VERSION ""

NS_ :

BS_:

BU_: FUSION IVI HMI Telltale

BO_ 278 FD_VCU1: 8 FUSION
 SG_ XWDMode : 57|2@0+ (1,0) [0|2] "" IVI
 SG_ PwrSta : 63|3@0+ (1,0) [0|5] "" IVI,HMI,Telltale
 SG_ DCDCVoltSetpoint : 55|8@0+ (0.0235,12) [12|17.9925] "V" Vector__XXX
 SG_ DCDCEnaReq : 40|1@0+ (1,0) [0|1] "" Vector__XXX
 SG_ Fr_MCUEnaReq : 41|1@0+ (1,0) [0|1] "" Vector__XXX
 SG_ Rr_MCUEnaReq : 42|1@0+ (1,0) [0|1] "" Vector__XXX
 SG_ HVBatCnctReq : 43|1@0+ (1,0) [0|1] "" Vector__XXX
 SG_ ActiveDischReq : 44|1@0+ (1,0) [0|1] "" Vector__XXX
 SG_ PrkReq : 45|1@0+ (1,0) [0|1] "" Vector__XXX
 SG_ Fr_ActvDmpDisabReq : 46|1@0+ (1,0) [0|1] "" Vector__XXX
 SG_ Rr_ActvDmpDisabReq : 47|1@0+ (1,0) [0|1] "" Vector__XXX
 SG_ HVSysReadyToCharge : 33|2@0+ (1,0) [0|3] "" Vector__XXX
 SG_ ShiftGearPosn : 38|3@0+ (1,0) [0|7] "" IVI
 SG_ LVChrgFuncStaChk : 25|2@0+ (1,0) [0|2] "" IVI
 SG_ CC_Crl_Sta : 28|3@0+ (1,0) [0|7] "" IVI
 SG_ MSA_Crl_Sta : 31|3@0+ (1,0) [0|7] "" IVI
 SG_ DemoModeStaChk : 17|2@0+ (1,0) [0|2] "" IVI
 SG_ CoastDwModeStaChk : 19|2@0+ (1,0) [0|2] "" IVI
 SG_ DynoModeStaChk : 21|2@0+ (1,0) [0|2] "" IVI
 SG_ Dr_SeatSta : 23|2@0+ (1,0) [0|2] "" IVI
 SG_ FalseNPrevent_Sta : 8|1@0+ (1,0) [0|1] "" IVI
 SG_ DisengageP_Fail : 9|1@0+ (1,0) [0|1] "" IVI
 SG_ EngageP_Fail : 10|1@0+ (1,0) [0|1] "" IVI
 SG_ CreepSW_Sta : 11|1@0+ (1,0) [0|1] "" IVI
 SG_ RC_VCU1_CAN2 : 15|4@0+ (1,0) [0|15] "" Vector__XXX
 SG_ CS_VCU1_CAN2 : 7|8@0+ (1,0) [0|255] "" Vector__XXX
 SG_ VCU_OPDHold : 39|1@0+ (1,0) [0|1] "" IVI
 SG_ FDC_VCU_PwrSaveReq_Cmd : 35|1@0+ (1,0) [0|1] "" IVI

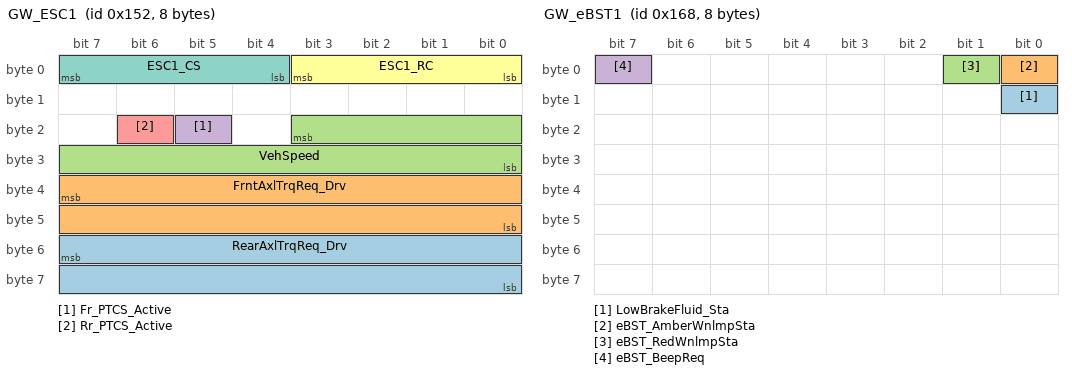
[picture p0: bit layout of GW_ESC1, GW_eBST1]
BO_ 338 GW_ESC1: 8 FUSION
 SG_ RearAxlTrqReq_Drv : 55|16@0+ (0.5,-5300) [0|5300] "Nm" Vector__XXX
 SG_ FrntAxlTrqReq_Drv : 39|16@0+ (0.5,-5300) [0|5300] "Nm" Vector__XXX
 SG_ VehSpeed : 19|12@0+ (0.125,0) [0|255.875] "km/h" IVI,HMI,Telltale
 SG_ Fr_PTCS_Active : 21|1@0+ (1,0) [0|1] "" Vector__XXX
 SG_ Rr_PTCS_Active : 22|1@0+ (1,0) [0|1] "" Vector__XXX
 SG_ ESC1_RC : 3|4@0+ (1,0) [0|15] "" Vector__XXX
 SG_ ESC1_CS : 7|4@0+ (1,0) [0|15] "" Vector__XXX

BO_ 360 GW_eBST1: 8 FUSION
 SG_ LowBrakeFluid_Sta : 8|1@0+ (1,0) [0|1] "" IVI
 SG_ eBST_AmberWnlmpSta : 0|1@0+ (1,0) [0|1] "" IVI,Telltale
 SG_ eBST_RedWnlmpSta : 1|1@0+ (1,0) [0|1] "" IVI
 SG_ eBST_BeepReq : 7|1@0+ (1,0) [0|1] "" IVI

BO_ 369 GW_BMS1: 16 FUSION
 SG_ HVBPwrAvailChrg30 : 115|12@0+ (0.2,0) [0|819] "KW" Vector__XXX
 SG_ HVBPwrAvailDchrg30 : 111|12@0+ (0.2,0) [0|819] "KW" Vector__XXX
 SG_ HVBPwrAvailChrg : 91|12@0+ (0.2,0) [0|819] "KW" Vector__XXX
 SG_ HVBPwrAvailDchrg : 87|12@0+ (0.2,0) [0|819] "KW" Vector__XXX
 SG_ HVBPwrAvailChrg60 : 67|12@0+ (0.2,0) [0|819] "KW" Vector__XXX
 SG_ HVBPwrAvailDchrg60 : 63|12@0+ (0.2,0) [0|819] "KW" Vector__XXX
 SG_ HVBattCurr : 46|15@0+ (0.1,-1000) [-1000|2276.5] "A" IVI
 SG_ HVBattVolt : 28|13@0+ (0.1,0) [0|819] "V" IVI
 SG_ BMSRolCnct_1 : 15|4@0+ (1,0) [0|15] "" Vector__XXX
 SG_ BMSChckSum_1 : 7|8@0+ (1,0) [0|255] "" Vector__XXX

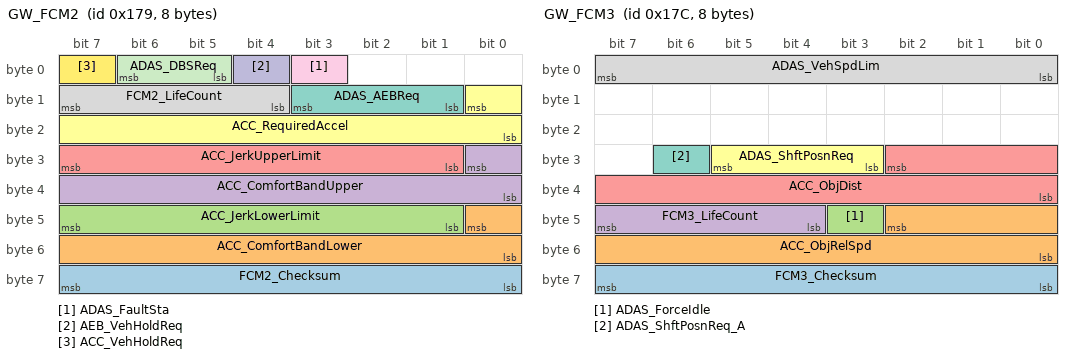
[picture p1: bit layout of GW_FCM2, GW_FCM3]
BO_ 377 GW_FCM2: 8 FUSION
 SG_ FCM2_Checksum : 63|8@0+ (1,0) [0|255] "" Vector__XXX
 SG_ ACC_ComfortBandLower : 40|9@0+ (0.05,-15) [-15|10.55] "m/s^2" Vector__XXX
 SG_ ACC_JerkLowerLimit : 47|7@0+ (0.1,-6) [-6|6.7] "m/s^3" Vector__XXX
 SG_ ACC_ComfortBandUpper : 24|9@0+ (0.05,-15) [-15|10.55] "m/s^2" Vector__XXX
 SG_ ACC_JerkUpperLimit : 31|7@0+ (0.1,-6) [-6|6.7] "m/s^3" Vector__XXX
 SG_ ACC_RequiredAccel : 8|9@0+ (0.05,-15) [-15|10.55] "m/s^2" Vector__XXX
 SG_ ADAS_AEBReq : 11|3@0+ (1,0) [0|7] "" IVI
 SG_ FCM2_LifeCount : 15|4@0+ (1,0) [0|15] "" Vector__XXX
 SG_ ADAS_FaultSta : 3|1@0+ (1,0) [0|1] "" Vector__XXX
 SG_ AEB_VehHoldReq : 4|1@0+ (1,0) [0|1] "" Vector__XXX
 SG_ ADAS_DBSReq : 6|2@0+ (1,0) [0|3] "" Vector__XXX
 SG_ ACC_VehHoldReq : 7|1@0+ (1,0) [0|1] "" Vector__XXX

BO_ 378 GW_BMS6: 12 FUSION
 SG_ BMS_Warn_1 : 88|1@0+ (1,0) [0|1] "" Vector__XXX
 SG_ BMS_Warn_2 : 89|1@0+ (1,0) [0|1] "" Vector__XXX
 SG_ BMS_Warn_3 : 90|1@0+ (1,0) [0|1] "" Vector__XXX
 SG_ BMS_Warn_4 : 91|1@0+ (1,0) [0|1] "" Vector__XXX
 SG_ BMS_Warn_5 : 92|1@0+ (1,0) [0|1] "" Vector__XXX
 SG_ BMS_Warn_6 : 93|1@0+ (1,0) [0|1] "" Vector__XXX
 SG_ BMS_Warn_7 : 94|1@0+ (1,0) [0|1] "" Vector__XXX
 SG_ BMS_Warn_8 : 95|1@0+ (1,0) [0|1] "" Vector__XXX
 SG_ HVBOvrTempWarn : 81|2@0+ (1,0) [0|2] "" IVI
 SG_ HVBUndrTempWarn : 83|2@0+ (1,0) [0|2] "" Vector__XXX
 SG_ HVBOvrVoltErr : 84|1@0+ (1,0) [0|1] "" Vector__XXX
 SG_ HVBUndrVoltErr : 85|1@0+ (1,0) [0|1] "" Vector__XXX
 SG_ HVBShrtChrgCurrErr : 86|1@0+ (1,0) [0|1] "" Vector__XXX
 SG_ HVBShrtDischrgCurrErr : 87|1@0+ (1,0) [0|1] "" Vector__XXX
 SG_ HVBOvrChrgCurrErr : 72|1@0+ (1,0) [0|1] "" Vector__XXX
 SG_ HVBOvrDchrgCurErr : 73|1@0+ (1,0) [0|1] "" Vector__XXX
 SG_ HVBOvrTempErr : 74|1@0+ (1,0) [0|1] "" IVI
 SG_ HVBUndrTempErr : 75|1@0+ (1,0) [0|1] "" Vector__XXX
 SG_ HVBOvrSOCErr : 76|1@0+ (1,0) [0|1] "" Vector__XXX
 SG_ HVBUndrSOCErr : 77|1@0+ (1,0) [0|1] "" Vector__XXX
 SG_ HVBSOCJumpError : 78|1@0+ (1,0) [0|1] "" Vector__XXX
 SG_ HVBHVILErr : 79|1@0+ (1,0) [0|1] "" Vector__XXX
 SG_ DCChrgSysShockErr : 64|1@0+ (1,0) [0|1] "" Vector__XXX
 SG_ BMS_READY : 65|1@0+ (1,0) [0|1] "" Vector__XXX
 SG_ HVBContactorSta : 66|1@0+ (1,0) [0|1] "" IVI
 SG_ HVBPrechrgSta : 69|2@0+ (1,0) [0|3] "" Vector__XXX
 SG_ HVBTempDiffErr : 70|1@0+ (1,0) [0|1] "" Vector__XXX
 SG_ HVILSta : 71|1@0+ (1,0) [0|1] "" Vector__XXX
 SG_ HVBattReady4Pre : 57|2@0+ (1,0) [0|2] "" Vector__XXX
 SG_ ChrgPlugSta : 59|2@0+ (1,0) [0|3] "" IVI
 SG_ ExtChrgSta : 61|2@0+ (1,0) [0|3] "" IVI
 SG_ HVBPreheatPrecoolSta : 63|2@0+ (1,0) [0|2] "" Vector__XXX
 SG_ IsoDetSta : 48|1@0+ (1,0) [0|1] "" Vector__XXX
 SG_ SystemUncomErr : 49|1@0+ (1,0) [0|1] "" Vector__XXX
 SG_ CellUnconsistErr : 50|1@0+ (1,0) [0|1] "" Vector__XXX
 SG_ HVBCellOvrVoltWarn : 53|2@0+ (1,0) [0|2] "" Vector__XXX
 SG_ HVBCellUdrVoltWarn : 55|2@0+ (1,0) [0|2] "" Vector__XXX
 SG_ HVBCellOvrVoltErr : 40|1@0+ (1,0) [0|1] "" Vector__XXX
 SG_ HVBCellUndrVoltErr : 41|1@0+ (1,0) [0|1] "" Vector__XXX
 SG_ HVBCellUnbalanErr : 42|1@0+ (1,0) [0|1] "" Vector__XXX
 SG_ ChrgInLockReq : 45|2@0+ (1,0) [0|2] "" Vector__XXX
 SG_ DisChrgPlugErr : 47|2@0+ (1,0) [0|3] "" IVI
 SG_ HVBChrgErr : 39|8@0+ (1,0) [0|255] "" IVI
 SG_ V2LSta : 25|2@0+ (1,0) [0|3] "" IVI
 SG_ BMSRolCnct : 15|4@0+ (1,0) [0|15] "" Vector__XXX
 SG_ BMSChckSum : 7|8@0+ (1,0) [0|255] "" Vector__XXX

BO_ 380 GW_FCM3: 8 FUSION
 SG_ FCM3_Checksum : 63|8@0+ (1,0) [0|255] "" Vector__XXX
 SG_ ACC_ObjRelSpd : 42|11@0+ (0.1,-100) [-100|104.6] "m/s" IVI
 SG_ ADAS_ForceIdle : 43|1@0+ (1,0) [0|1] "" Vector__XXX
 SG_ FCM3_LifeCount : 47|4@0+ (1,0) [0|15] "" Vector__XXX
 SG_ ACC_ObjDist : 26|11@0+ (0.1,0) [0|204.6] "m" IVI
 SG_ ADAS_ShftPosnReq : 29|3@0+ (1,0) [0|7] "" Vector__XXX
 SG_ ADAS_ShftPosnReq_A : 30|1@0+ (1,0) [0|1] "" Vector__XXX
 SG_ ADAS_VehSpdLim : 7|8@0+ (1,0) [0|254] "" IVI

BO_ 383 FD_VMC1: 8 FUSION
 SG_ CCMSA_SpdWar : 5|1@0+ (1,0) [0|1] "" IVI

BO_ 386 FD_THCM1: 20 FUSION
 SG_ Rr_Coolanttemp : 144|9@0+ (1,-40) [-40|214] "Deg^C" Vector__XXX
 SG_ Rr_Coolantflow : 150|6@0+ (0.25,0) [0|15.75] "L/min" Vector__XXX
 SG_ FD_AGS_Cmd : 143|8@0+ (1,0) [0|255] "" IVI
 SG_ sigClntTHvBattOut : 135|8@0+ (0.5,-40) [-40|85] "Deg^C" Vector__XXX
 SG_ sigCbnSolarLeft : 127|8@0+ (5,0) [0|1265] "W" Vector__XXX
 SG_ CabinMode : 115|4@0+ (1,0) [0|9] "" Vector__XXX
 SG_ BatteryMode : 118|3@0+ (1,0) [0|5] "" Vector__XXX
 SG_ FD_RecyAuto_Cmd : 111|3@0+ (1,0) [0|6] "" Vector__XXX
 SG_ sigCbnSolarRight : 103|8@0+ (5,0) [0|1265] "W" Vector__XXX
 SG_ sigAmbAirT : 95|8@0+ (0.5,-40) [-40|85] "Deg^C" IVI
 SG_ sigCbnAirT : 87|8@0+ (0.5,-40) [-40|85] "Deg^C" IVI
 SG_ sigCbnPTCPwrAct : 79|8@0+ (50,0) [0|12650] "W" Vector__XXX
 SG_ sigClmtCmprPwrAct : 71|8@0+ (50,0) [0|12650] "W" Vector__XXX
 SG_ Fr_Coolantflow : 61|6@0+ (0.25,0) [0|15.75] "L/min" Vector__XXX
 SG_ EDriveMode : 63|2@0+ (1,0) [0|2] "" Vector__XXX
 SG_ sigSetTempZon1St : 53|6@0+ (0.5,17) [17|32] "Deg^C" IVI
 SG_ HPThermalRecoveryReq : 55|2@0+ (1,0) [0|1] "" Vector__XXX
 SG_ sigSetTempZon2St : 45|6@0+ (0.5,17) [17|32] "Deg^C" IVI
 SG_ sigHvacSt : 46|1@0+ (1,0) [0|1] "" IVI
 SG_ sigRecircSt : 47|1@0+ (1,0) [0|1] "" IVI
 SG_ sigSetTempZon3St : 37|6@0+ (0.5,17) [17|32] "Deg^C" IVI
 SG_ sigDfrstSt : 38|1@0+ (1,0) [0|1] "" IVI
 SG_ CCU_SyncLampSts : 39|1@0+ (1,0) [0|1] "" IVI
 SG_ sigAirIntenZon3St : 27|4@0+ (1,0) [0|15] "" IVI
 SG_ sigAirIntenZon1St : 31|4@0+ (1,0) [0|15] "" IVI
 SG_ sigWindDirZon3St : 18|3@0+ (1,0) [0|7] "" IVI
 SG_ CCU_FrtOnOffLampSts : 19|1@0+ (1,0) [0|1] "" IVI
 SG_ sigWindDirZon1St : 22|3@0+ (1,0) [0|7] "" IVI
 SG_ CCU_RrOnOffLampSts : 23|1@0+ (1,0) [0|1] "" IVI
 SG_ Fr_Coolanttemp : 0|9@0+ (1,-40) [-40|214] "Deg^C" Vector__XXX
 SG_ CCU_ACMaxLampSts : 1|1@0+ (1,0) [0|1] "" IVI
 SG_ CCU_AutoLampSts : 2|1@0+ (1,0) [0|1] "" IVI
 SG_ CCU_AutoMidLampSts : 3|1@0+ (1,0) [0|1] "" IVI
 SG_ CCU_EcoSts : 4|1@0+ (1,0) [0|1] "" IVI
 SG_ CCU_Dispaly_Request : 5|1@0+ (1,0) [0|1] "" IVI
 SG_ CCU_ACLampSts : 6|1@0+ (1,0) [0|1] "" IVI
 SG_ CCU_HEATMaxLampSts : 7|1@0+ (1,0) [0|1] "" Vector__XXX

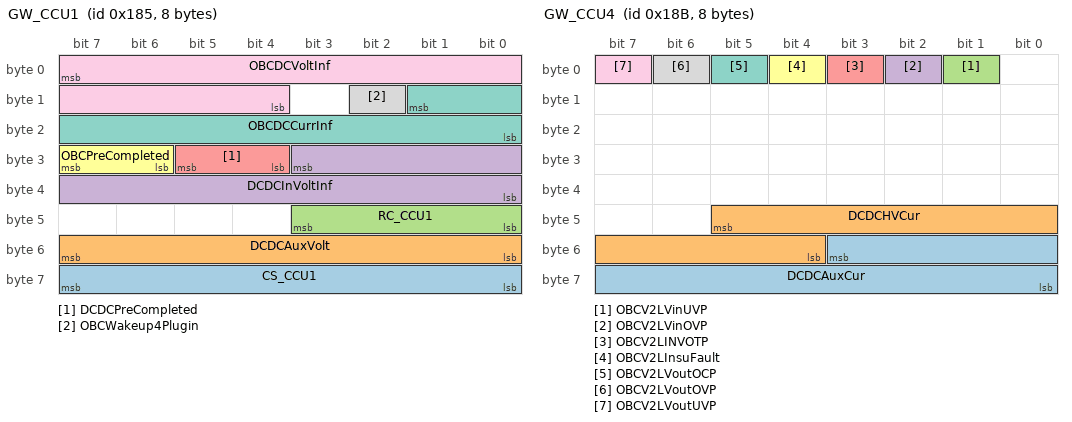
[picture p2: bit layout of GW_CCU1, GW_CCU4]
BO_ 389 GW_CCU1: 8 FUSION
 SG_ CS_CCU1 : 63|8@0+ (1,0) [0|255] "" Vector__XXX
 SG_ DCDCAuxVolt : 55|8@0+ (0.047,8) [8|19.938] "V" IVI
 SG_ RC_CCU1 : 43|4@0+ (1,0) [0|15] "" Vector__XXX
 SG_ DCDCInVoltInf : 27|12@0+ (0.25,0) [0|1023.5] "V" Vector__XXX
 SG_ DCDCPreCompleted : 29|2@0+ (1,0) [0|2] "" Vector__XXX
 SG_ OBCPreCompleted : 31|2@0+ (1,0) [0|2] "" Vector__XXX
 SG_ OBCDCCurrInf : 9|10@0+ (0.1,-25.5) [-25.5|76.7] "A" Vector__XXX
 SG_ OBCWakeup4Plugin : 10|1@0+ (1,0) [0|1] "" Vector__XXX
 SG_ OBCDCVoltInf : 7|12@0+ (0.3,0) [0|1228.2] "V" Vector__XXX

BO_ 395 GW_CCU4: 8 FUSION
 SG_ DCDCAuxCur : 51|12@0+ (0.1,0) [0|409.5] "A" IVI
 SG_ DCDCHVCur : 45|10@0+ (0.02,0) [0|20.46] "A" Vector__XXX
 SG_ OBCV2LVinUVP : 1|1@0+ (1,0) [0|1] "" Vector__XXX
 SG_ OBCV2LVinOVP : 2|1@0+ (1,0) [0|1] "" Vector__XXX
 SG_ OBCV2LINVOTP : 3|1@0+ (1,0) [0|1] "" Vector__XXX
 SG_ OBCV2LInsuFault : 4|1@0+ (1,0) [0|1] "" Vector__XXX
 SG_ OBCV2LVoutOCP : 5|1@0+ (1,0) [0|1] "" Vector__XXX
 SG_ OBCV2LVoutOVP : 6|1@0+ (1,0) [0|1] "" Vector__XXX
 SG_ OBCV2LVoutUVP : 7|1@0+ (1,0) [0|1] "" Vector__XXX

BO_ 402 GW_MCU_R1: 32 FUSION
 SG_ Rr_EDUTqReqFbk : 243|12@0+ (1,-1022) [-1022|1022] "Nm" Vector__XXX
 SG_ Rr_MCUEnaSta : 244|1@0+ (1,0) [0|1] "" Vector__XXX
 SG_ Rr_EDUOpratingSta : 245|1@0+ (1,0) [0|1] "" Vector__XXX
 SG_ Rr_EDURotateDirction : 247|2@0+ (1,0) [0|2] "" Vector__XXX
 SG_ Rr_EDURealTMTq : 227|12@0+ (1,-1022) [-1022|1022] "Nm" IVI
 SG_ Rr_TMSpd : 215|16@0+ (1,-17000) [-17000|17000] "RPM" IVI
 SG_ Rr_MCUReady4Pre : 200|1@0+ (1,0) [0|1] "" Vector__XXX
 SG_ Rr_ActvDmpDisabSta : 201|1@0+ (1,0) [0|1] "" Vector__XXX
 SG_ Rr_EDUDrtSta : 202|1@0+ (1,0) [0|1] "" IVI
 SG_ Rr_MCUDischrgSta : 203|1@0+ (1,0) [0|1] "" Vector__XXX
 SG_ Rr_MCUReady : 207|1@0+ (1,0) [0|1] "" Vector__XXX
 SG_ Rr_MCUDCBusVolt : 191|16@0+ (0.1,0) [0|4000] "V" Vector__XXX
 SG_ Rr_MCUDCBusCurr : 174|15@0+ (0.1,-1500) [-1500|1500] "A" Vector__XXX
 SG_ Rr_MCUTemp : 167|9@0+ (1,-40) [-40|254] "Deg^C" IVI
 SG_ Rr_TMTemp : 144|9@0+ (1,-40) [-40|254] "Deg^C" IVI
 SG_ Rr_MCUErr : 143|8@0+ (1,0) [0|255] "" Vector__XXX
 SG_ Rr_TMid : 126|15@0+ (0.1,-1500) [-1500|1500] "A" Vector__XXX
 SG_ Rr_TMiq : 110|15@0+ (0.1,-1500) [-1500|1500] "A" Vector__XXX
 SG_ Rr_MotorAvailTq : 91|12@0+ (1,0) [0|1022] "Nm" IVI
 SG_ Rr_RegenAvailTq : 87|12@0+ (1,-1022) [-1022|0] "Nm" Vector__XXX
 SG_ Rr_MCUIGN_sta : 72|1@0+ (1,0) [0|1] "" Vector__XXX
 SG_ Rr_Reserved_bits : 79|7@0+ (1,0) [0|127] "" Vector__XXX
 SG_ Rr_MCUBAT : 71|8@0+ (0.1,0) [0|25.4] "V" Vector__XXX
 SG_ Rr_MCUSysSta : 59|4@0+ (1,0) [0|15] "" Vector__XXX
 SG_ MCUWarn_R : 10|3@0+ (1,0) [0|7] "" Vector__XXX
 SG_ Rr_MCU1RolCnt : 15|4@0+ (1,0) [0|15] "" Vector__XXX
 SG_ Rr_MCU1Chksum : 7|8@0+ (1,0) [0|255] "" Vector__XXX

BO_ 406 GW_MCU_F1: 32 FUSION
 SG_ Fr_EDUTqReqFbk : 243|12@0+ (1,-1022) [-1022|1022] "Nm" Vector__XXX
 SG_ Fr_MCUEnaSta : 244|1@0+ (1,0) [0|1] "" Vector__XXX
 SG_ Fr_EDUOpratingSta : 245|1@0+ (1,0) [0|1] "" Vector__XXX
 SG_ Fr_EDURotateDirction : 247|2@0+ (1,0) [0|2] "" Vector__XXX
 SG_ Fr_EDURealTMTq : 227|12@0+ (1,-1022) [-1022|1022] "Nm" IVI
 SG_ Fr_TMSpd : 215|16@0+ (1,-17000) [-17000|17000] "RPM" IVI
 SG_ Fr_MCUReady4Pre : 200|1@0+ (1,0) [0|1] "" Vector__XXX
 SG_ Fr_ActvDmpDisabSta : 201|1@0+ (1,0) [0|1] "" Vector__XXX
 SG_ Fr_EDUDrtSta : 202|1@0+ (1,0) [0|1] "" IVI
 SG_ Fr_MCUDischrgSta : 203|1@0+ (1,0) [0|1] "" Vector__XXX
 SG_ Fr_MCUDCBusVolt : 191|16@0+ (0.1,0) [0|4000] "V" Vector__XXX
 SG_ Fr_MCUDCBusCurr : 174|15@0+ (0.1,-1500) [-1500|1500] "A" Vector__XXX
 SG_ Fr_MCUTemp : 167|9@0+ (1,-40) [-40|254] "Deg^C" Vector__XXX
 SG_ Fr_TMTemp : 144|9@0+ (1,-40) [-40|254] "Deg^C" Vector__XXX
 SG_ Fr_MCUErr : 143|8@0+ (1,0) [0|255] "" Vector__XXX
 SG_ Fr_TMid : 126|15@0+ (0.1,-1500) [-1500|1500] "A" Vector__XXX
 SG_ Fr_TMiq : 110|15@0+ (0.1,-1500) [-1500|1500] "A" Vector__XXX
 SG_ Fr_MotorAvailTq : 91|12@0+ (1,0) [0|1022] "Nm" IVI
 SG_ Fr_RegenAvailTq : 87|12@0+ (1,-1022) [-1022|0] "Nm" Vector__XXX
 SG_ Fr_MCUIGN_sta : 72|1@0+ (1,0) [0|1] "" Vector__XXX
 SG_ Fr_Reserved_bits : 79|7@0+ (1,0) [0|127] "" Vector__XXX
 SG_ Fr_MCUBAT : 71|8@0+ (0.1,0) [0|25.4] "V" Vector__XXX
 SG_ Fr_MCUSysSta : 59|4@0+ (1,0) [0|15] "" Vector__XXX
 SG_ MCUWarn_F : 10|3@0+ (1,0) [0|7] "" Vector__XXX
 SG_ Fr_MCUReady : 11|1@0+ (1,0) [0|1] "" Vector__XXX
 SG_ Fr_MCU1RolCnt : 15|4@0+ (1,0) [0|15] "" Vector__XXX
 SG_ Fr_MCU1Chksum : 7|8@0+ (1,0) [0|255] "" Vector__XXX

BO_ 408 GW_MCU_F2: 12 FUSION
 SG_ Fr_LLCTemp : 80|9@0+ (1,-40) [-40|214] "Deg^C" Vector__XXX
 SG_ Fr_LLCflowReq : 87|6@0+ (0.25,0) [0|15.5] "L/min" Vector__XXX
 SG_ Fr_EOP_SpdSet : 67|12@0+ (1,0) [0|4000] "RPM" Vector__XXX
 SG_ Fr_Failcode1 : 63|8@0+ (1,0) [0|255] "" Vector__XXX
 SG_ Fr_Failcode2 : 55|8@0+ (1,0) [0|255] "" Vector__XXX
 SG_ Fr_Failcodehistory1 : 41|2@0+ (1,0) [0|2] "" Vector__XXX
 SG_ Fr_Failcodehistory2 : 43|2@0+ (1,0) [0|2] "" Vector__XXX
 SG_ Fr_TMTempWarn : 45|2@0+ (1,0) [0|3] "" IVI
 SG_ Fr_MCUTempWarn : 47|2@0+ (1,0) [0|3] "" IVI
 SG_ Fr_CoolanttempReq : 24|9@0+ (1,-40) [-40|214] "Deg^C" Vector__XXX
 SG_ Fr_MCU2RolCnt : 15|4@0+ (1,0) [0|15] "" Vector__XXX
 SG_ Fr_MCU2Chksum : 7|8@0+ (1,0) [0|255] "" Vector__XXX
 SG_ MCU_F_ResetCnt_Sta : 23|8@0+ (1,0) [0|255] "" Vector__XXX

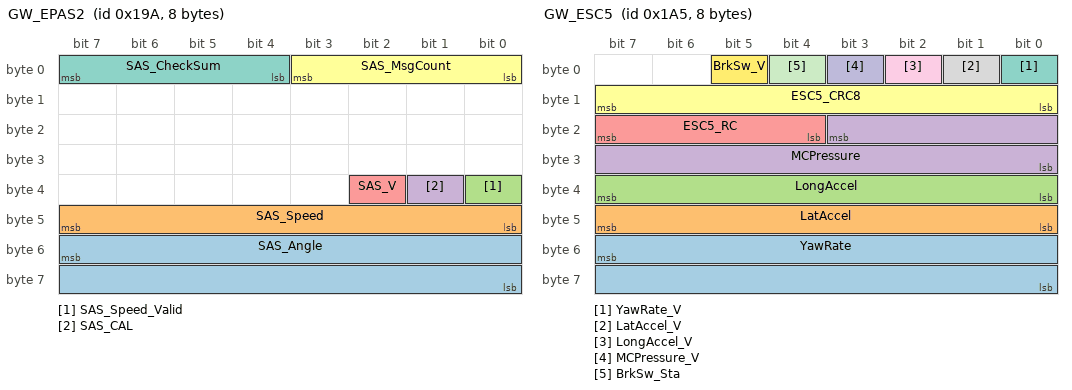
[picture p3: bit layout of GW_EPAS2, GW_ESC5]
BO_ 410 GW_EPAS2: 8 FUSION
 SG_ SAS_Angle : 55|16@0+ (0.1,-900) [-900|900] "Deg" IVI
 SG_ SAS_Speed : 47|8@0+ (4,0) [0|1020] "Deg/s" Vector__XXX
 SG_ SAS_Speed_Valid : 32|1@0+ (1,0) [0|1] "" Vector__XXX
 SG_ SAS_CAL : 33|1@0+ (1,0) [0|1] "" Vector__XXX
 SG_ SAS_V : 34|1@0+ (1,0) [0|1] "" IVI
 SG_ SAS_MsgCount : 3|4@0+ (1,0) [0|15] "" Vector__XXX
 SG_ SAS_CheckSum : 7|4@0+ (1,0) [0|15] "" Vector__XXX

BO_ 412 GW_MCU_R2: 12 FUSION
 SG_ Rr_LLCTemp : 80|9@0+ (1,-40) [-40|214] "Deg^C" Vector__XXX
 SG_ Rr_LLCflowReq : 87|6@0+ (0.25,0) [0|15.5] "L/min" Vector__XXX
 SG_ Rr_EOP_SpdSet : 67|12@0+ (1,0) [0|4000] "RPM" Vector__XXX
 SG_ Rr_Failcode1 : 63|8@0+ (1,0) [0|255] "" Vector__XXX
 SG_ Rr_Failcode2 : 55|8@0+ (1,0) [0|255] "" Vector__XXX
 SG_ Rr_Failcodehistory1 : 41|2@0+ (1,0) [0|2] "" Vector__XXX
 SG_ Rr_Failcodehistory2 : 43|2@0+ (1,0) [0|2] "" Vector__XXX
 SG_ Rr_TMTempWarn : 45|2@0+ (1,0) [0|3] "" IVI
 SG_ Rr_MCUTempWarn : 47|2@0+ (1,0) [0|3] "" IVI
 SG_ Rr_CoolanttempReq : 24|9@0+ (1,-40) [-40|214] "" Vector__XXX
 SG_ Rr_MCU2RolCnt : 15|4@0+ (1,0) [0|15] "" Vector__XXX
 SG_ Rr_MCU2Chksum : 7|8@0+ (1,0) [0|255] "" Vector__XXX
 SG_ MCU_R_ResetCnt_Sta : 23|8@0+ (1,0) [0|255] "" Vector__XXX

BO_ 419 GW_ESC4: 8 FUSION
 SG_ Red_WnlmpSta : 59|1@0+ (1,0) [0|1] "" IVI
 SG_ ABS_WnlmpSta : 60|1@0+ (1,0) [0|1] "" IVI,Telltale
 SG_ ESC_Off_lmpSta : 61|1@0+ (1,0) [0|1] "" IVI
 SG_ ESC_WnlmpSta : 63|2@0+ (1,0) [0|2] "" IVI,Telltale
 SG_ GRADE : 55|8@0+ (0.354331,-45) [-45|45] "Deg" Vector__XXX
 SG_ EBD_Active : 44|1@0+ (1,0) [0|1] "" Vector__XXX
 SG_ ABS_Active : 45|1@0+ (1,0) [0|1] "" IVI
 SG_ TCS_Active : 46|1@0+ (1,0) [0|1] "" Vector__XXX
 SG_ ESC_Active : 47|1@0+ (1,0) [0|1] "" Vector__XXX
 SG_ HBB_Active : 32|1@0+ (1,0) [0|1] "" IVI
 SG_ PBA_Active : 33|1@0+ (1,0) [0|1] "" IVI
 SG_ HSA_Active : 34|1@0+ (1,0) [0|1] "" IVI
 SG_ AVH_Active : 35|1@0+ (1,0) [0|1] "" IVI
 SG_ Amber_WnlmpSta : 36|1@0+ (1,0) [0|1] "" IVI,Telltale
 SG_ BTCS_Active : 37|1@0+ (1,0) [0|1] "" IVI
 SG_ ESS_Active : 38|1@0+ (1,0) [0|1] "" IVI
 SG_ HDD_Active : 39|1@0+ (1,0) [0|1] "" IVI
 SG_ EBD_Failed : 24|1@0+ (1,0) [0|1] "" IVI
 SG_ ABS_Failed : 25|1@0+ (1,0) [0|1] "" IVI
 SG_ TCS_Failed : 26|1@0+ (1,0) [0|1] "" IVI
 SG_ ESC_Failed : 27|1@0+ (1,0) [0|1] "" IVI
 SG_ HBB_Failed : 28|1@0+ (1,0) [0|1] "" IVI
 SG_ PBA_Failed : 29|1@0+ (1,0) [0|1] "" IVI
 SG_ HSA_Failed : 30|1@0+ (1,0) [0|1] "" IVI
 SG_ AVH_Failed : 31|1@0+ (1,0) [0|1] "" IVI
 SG_ HDD_Failed : 16|1@0+ (1,0) [0|1] "" IVI
 SG_ ESC_OFF_Status : 18|2@0+ (1,0) [0|2] "" IVI
 SG_ ESC_BeepReq : 15|1@0+ (1,0) [0|1] "" IVI
 SG_ SystemVoltage : 7|8@0+ (0.08,0) [0|20.32] "V" Vector__XXX

BO_ 421 GW_ESC5: 8 FUSION
 SG_ YawRate : 55|16@0+ (0.1,-100) [-100|100] "Deg/s" Vector__XXX
 SG_ LatAccel : 47|8@0+ (0.01,-1.27) [-1.27|1.27] "G's" Vector__XXX
 SG_ LongAccel : 39|8@0+ (0.01,-1.27) [-1.27|1.27] "G's" Vector__XXX
 SG_ MCPressure : 19|12@0+ (0.1,-9.7) [-9.7|195] "bar" Vector__XXX
 SG_ ESC5_RC : 23|4@0+ (1,0) [0|15] "" Vector__XXX
 SG_ ESC5_CRC8 : 15|8@0+ (1,0) [0|255] "" Vector__XXX
 SG_ YawRate_V : 0|1@0+ (1,0) [0|1] "" Vector__XXX
 SG_ LatAccel_V : 1|1@0+ (1,0) [0|1] "" Vector__XXX
 SG_ LongAccel_V : 2|1@0+ (1,0) [0|1] "" Vector__XXX
 SG_ MCPressure_V : 3|1@0+ (1,0) [0|1] "" Vector__XXX
 SG_ BrkSw_Sta : 4|1@0+ (1,0) [0|1] "" IVI
 SG_ BrkSw_V : 5|1@0+ (1,0) [0|1] "" IVI

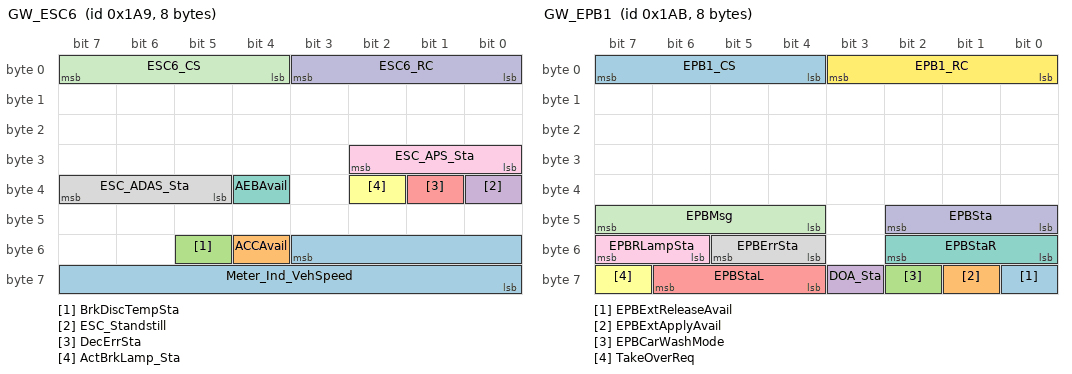
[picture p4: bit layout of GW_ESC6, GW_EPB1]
BO_ 425 GW_ESC6: 8 FUSION
 SG_ Meter_Ind_VehSpeed : 51|12@0+ (0.125,0) [0|300] "km/h" IVI
 SG_ ACCAvail : 52|1@0+ (1,0) [0|1] "" Vector__XXX
 SG_ BrkDiscTempSta : 53|1@0+ (1,0) [0|1] "" IVI
 SG_ ESC_Standstill : 32|1@0+ (1,0) [0|1] "" Vector__XXX
 SG_ DecErrSta : 33|1@0+ (1,0) [0|1] "" Vector__XXX
 SG_ ActBrkLamp_Sta : 34|1@0+ (1,0) [0|1] "" IVI
 SG_ AEBAvail : 36|1@0+ (1,0) [0|1] "" IVI
 SG_ ESC_ADAS_Sta : 39|3@0+ (1,0) [0|6] "" IVI
 SG_ ESC_APS_Sta : 26|3@0+ (1,0) [0|5] "" Vector__XXX
 SG_ ESC6_RC : 3|4@0+ (1,0) [0|15] "" Vector__XXX
 SG_ ESC6_CS : 7|4@0+ (1,0) [0|15] "" Vector__XXX

BO_ 427 GW_EPB1: 8 FUSION
 SG_ EPBExtReleaseAvail : 56|1@0+ (1,0) [0|1] "" Vector__XXX
 SG_ EPBExtApplyAvail : 57|1@0+ (1,0) [0|1] "" Vector__XXX
 SG_ EPBCarWashMode : 58|1@0+ (1,0) [0|1] "" IVI
 SG_ DOA_Sta : 59|1@0+ (1,0) [0|1] "" IVI
 SG_ EPBStaL : 62|3@0+ (1,0) [0|7] "" IVI
 SG_ TakeOverReq : 63|1@0+ (1,0) [0|1] "" Vector__XXX
 SG_ EPBStaR : 50|3@0+ (1,0) [0|7] "" IVI
 SG_ EPBErrSta : 53|2@0+ (1,0) [0|2] "" IVI,Telltale
 SG_ EPBRLampSta : 55|2@0+ (1,0) [0|2] "" IVI
 SG_ EPBSta : 42|3@0+ (1,0) [0|4] "" IVI
 SG_ EPBMsg : 47|4@0+ (1,0) [0|12] "" IVI
 SG_ EPB1_RC : 3|4@0+ (1,0) [0|15] "" Vector__XXX
 SG_ EPB1_CS : 7|4@0+ (1,0) [0|15] "" Vector__XXX

BO_ 470 GW_CCU2: 12 FUSION
 SG_ OBCFaultSta : 89|2@0+ (1,0) [0|3] "" IVI
 SG_ DCDCFaultSta : 91|2@0+ (1,0) [0|3] "" Vector__XXX
 SG_ OBCReady4Pre : 92|1@0+ (1,0) [0|1] "" Vector__XXX
 SG_ DCDCReady4Pre : 93|1@0+ (1,0) [0|1] "" Vector__XXX
 SG_ OBCTemp : 87|9@0+ (0.3,-48) [-48|105.3] "Deg^C" Vector__XXX
 SG_ DCDCTemp : 79|8@0+ (0.75,-48) [-48|142.5] "Deg^C" Vector__XXX
 SG_ OBCDCP : 57|10@0+ (20,-7000) [-7000|13440] "W" Vector__XXX
 SG_ DCDCEnaSta : 58|1@0+ (1,0) [0|1] "" Vector__XXX
 SG_ OBCPluginSta : 59|1@0+ (1,0) [0|1] "" Vector__XXX
 SG_ OBCEnaSta : 60|1@0+ (1,0) [0|1] "" Vector__XXX
 SG_ OBCACCurrInf : 55|10@0+ (0.125,-40) [-40|87.75] "A" IVI
 SG_ OBCACVoltInf : 35|12@0+ (0.1,0) [0|409.4] "V" IVI
 SG_ OBC_AC_Cur_Lim : 37|2@0+ (1,0) [0|3] "" IVI
 SG_ OBCV2LSta : 9|2@0+ (1,0) [0|2] "" Vector__XXX
 SG_ ReqOBCV2LEna : 11|2@0+ (1,0) [0|2] "" Vector__XXX
 SG_ RC_CCU2 : 15|4@0+ (1,0) [0|15] "" Vector__XXX
 SG_ CS_CCU2 : 7|8@0+ (1,0) [0|255] "" Vector__XXX

BO_ 497 Zone_Dr_VCU: 20 FUSION
 SG_ DrPowerTemp2 : 127|16@0+ (0.01,-40) [-40|125] "Deg^C" Vector__XXX
 SG_ DrPowerTemp1 : 111|16@0+ (0.01,-40) [-40|125] "Deg^C" Vector__XXX
 SG_ DrCtrlTemp : 95|16@0+ (0.01,-40) [-40|125] "Deg^C" Vector__XXX
 SG_ DrCtrlBDVolt : 75|12@0+ (0.01,0) [0|36] "V" Vector__XXX
 SG_ DrPwrONA1Curr : 71|8@0+ (0.125,0) [0|31.875] "A" Vector__XXX
 SG_ DrPwrONA2Curr : 63|8@0+ (0.125,0) [0|31.875] "A" Vector__XXX
 SG_ DrPwrStdbyACurr : 55|8@0+ (0.125,0) [0|31.875] "A" Vector__XXX
 SG_ DrAuBoxPwrN1Curr : 47|8@0+ (0.125,0) [0|31.875] "A" Vector__XXX
 SG_ DrAuBoxPwrN2Curr : 39|8@0+ (0.125,0) [0|31.875] "A" Vector__XXX
 SG_ DrColumnSWFault : 17|2@0+ (1,0) [0|2] "" Vector__XXX
 SG_ DrTHCMFault : 19|2@0+ (1,0) [0|2] "" Vector__XXX
 SG_ DrPwrWindowECUFault : 21|2@0+ (1,0) [0|2] "" Vector__XXX
 SG_ DrInfoFault : 23|2@0+ (1,0) [0|2] "" Vector__XXX
 SG_ DrEOBDFault : 9|2@0+ (1,0) [0|2] "" Vector__XXX
 SG_ DrIVIFault : 11|2@0+ (1,0) [0|2] "" Vector__XXX
 SG_ DrPMMLimpHomeActReq : 13|1@0+ (1,0) [0|1] "" Vector__XXX
 SG_ DrPMMLVOutPErrLmp : 14|1@0+ (1,0) [0|1] "" Telltale
 SG_ DrPMMSysErrLmp : 15|1@0+ (1,0) [0|1] "" Telltale
 SG_ DrPwrSta : 78|3@0+ (1,0) [0|5] "" Vector__XXX
 SG_ DrPwrInformationSta : 79|1@0+ (1,0) [0|1] "" Vector__XXX
 SG_ ZDR_SYS_APMRetryCnt_Sta : 31|8@0+ (1,0) [0|255] "" Vector__XXX
 SG_ ZDR_SYS_CSWRetryCnt_Sta : 143|8@0+ (1,0) [0|255] "" Vector__XXX
 SG_ ZDR_SYS_BSWSleepReq_Sta : 150|1@0+ (1,0) [0|1] "" Vector__XXX
 SG_ DrAPWLINErr : 6|1@0+ (1,0) [0|1] "" Vector__XXX
 SG_ DrAPWStaErr : 7|1@0+ (1,0) [0|1] "" Vector__XXX
 SG_ DrONA1ErrSta : 5|1@0+ (1,0) [0|1] "" Vector__XXX
 SG_ DrPwrWinErrSta : 3|1@0+ (1,0) [0|1] "" Vector__XXX
 SG_ DrStdAErrSta : 4|1@0+ (1,0) [0|1] "" Vector__XXX
 SG_ DrInfoErrSta : 12|1@0+ (1,0) [0|1] "" Vector__XXX
 SG_ ZoneDrMalfunLevel : 2|3@0+ (1,0) [0|5] "" Vector__XXX
 SG_ ZDR_VCU_HWReset_Sta : 148|5@0+ (1,0) [0|31] "" Vector__XXX
 SG_ ZDR_VCU_PwrSupply_Sta : 149|1@0+ (1,0) [0|1] "" Vector__XXX

BO_ 498 Zone_Fr_VCU: 24 FUSION
 SG_ FrPowerTemp1 : 159|16@0+ (0.01,-40) [-40|125] "Deg^C" Vector__XXX
 SG_ FrPowerTemp2 : 143|16@0+ (0.01,-40) [-40|125] "Deg^C" Vector__XXX
 SG_ FrCtrlTemp : 127|16@0+ (0.01,-40) [-40|125] "Deg^C" Vector__XXX
 SG_ FrCtrlBDVolt : 107|12@0+ (0.01,0) [0|36] "V" Vector__XXX
 SG_ FrPwrStdbyA1PlusCurr : 103|8@0+ (0.125,0) [0|31.875] "A" Vector__XXX
 SG_ FrIRC_2Curr : 81|10@0+ (1,0) [0|1023] "mA" Vector__XXX
 SG_ FrPwrONA2Curr : 79|8@0+ (0.125,0) [0|31.875] "A" Vector__XXX
 SG_ FrPwrONA3Curr : 71|8@0+ (0.125,0) [0|31.875] "A" Vector__XXX
 SG_ FrPwrStdbyA2Curr : 63|8@0+ (0.125,0) [0|31.875] "A" Vector__XXX
 SG_ FrIRC_1Curr : 41|10@0+ (1,0) [0|1023] "mA" Vector__XXX
 SG_ FrPMMLimpHomeActReq : 45|1@0+ (1,0) [0|1] "" Telltale
 SG_ FrPMMLVOutPErrLmp : 46|1@0+ (1,0) [0|1] "" Vector__XXX
 SG_ FrPMMSysErrLmp : 47|1@0+ (1,0) [0|1] "" Vector__XXX
 SG_ FrPwrStdbyA1Fault : 33|2@0+ (1,0) [0|2] "" Vector__XXX
 SG_ FrEDU_INVERTERFault : 36|3@0+ (1,0) [0|7] "" Vector__XXX
 SG_ FrBMS_CCU_CIRFault : 39|3@0+ (1,0) [0|7] "" Vector__XXX
 SG_ FrPwrONA1Fault : 25|2@0+ (1,0) [0|2] "" Vector__XXX
 SG_ FrPwrStdbyA2PlusFault : 28|3@0+ (1,0) [0|7] "" Vector__XXX
 SG_ FrPwrStdbyA1PlusFault : 31|3@0+ (1,0) [0|7] "" Vector__XXX
 SG_ FrEDU_INVERTERCurr : 23|8@0+ (0.125,0) [0|31.875] "A" Vector__XXX
 SG_ FrBMS_CCU_CIRCurr : 15|8@0+ (0.125,0) [0|31.875] "A" Vector__XXX
 SG_ FrPwrStdbyA2PlusCurr : 7|8@0+ (0.125,0) [0|31.875] "A" Vector__XXX
 SG_ ZoneFrMalfunLevel : 44|3@0+ (1,0) [0|5] "" Vector__XXX
 SG_ ZFR_SYS_BMSCCURetryCnt_Sta : 175|8@0+ (1,0) [0|255] "" Vector__XXX
 SG_ ZFR_SYS_MCURetryCnt_Sta : 183|8@0+ (1,0) [0|255] "" Vector__XXX
 SG_ ZFR_SYS_BSWSleepReq_Sta : 87|1@0+ (1,0) [0|1] "" Vector__XXX
 SG_ FrBMSCCUCErr : 83|1@0+ (1,0) [0|1] "" Vector__XXX
 SG_ FrEDUErr : 82|1@0+ (1,0) [0|1] "" Vector__XXX
 SG_ FrStdA1PCErr : 86|1@0+ (1,0) [0|1] "" Vector__XXX
 SG_ FrStdA2PCErr : 85|1@0+ (1,0) [0|1] "" Vector__XXX
 SG_ FrStdA2PErr : 84|1@0+ (1,0) [0|1] "" Vector__XXX
 SG_ FrPwrSta : 110|3@0+ (1,0) [0|5] "" Vector__XXX
 SG_ ZFR_VCU_HWReset_Sta : 188|5@0+ (1,0) [0|31] "" Vector__XXX
 SG_ ZFR_VCU_PwrSupply_Sta : 111|1@0+ (1,0) [0|1] "" Vector__XXX

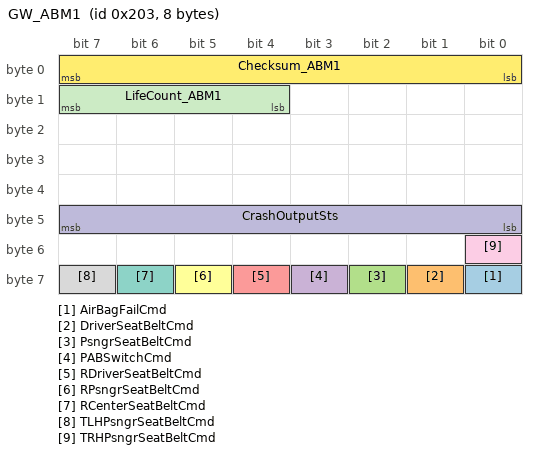
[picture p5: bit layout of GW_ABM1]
BO_ 515 GW_ABM1: 8 FUSION
 SG_ AirBagFailCmd : 56|1@0+ (1,0) [0|1] "" IVI
 SG_ DriverSeatBeltCmd : 57|1@0+ (1,0) [0|1] "" IVI
 SG_ PsngrSeatBeltCmd : 58|1@0+ (1,0) [0|1] "" IVI
 SG_ PABSwitchCmd : 59|1@0+ (1,0) [0|1] "" IVI
 SG_ RDriverSeatBeltCmd : 60|1@0+ (1,0) [0|1] "" IVI
 SG_ RPsngrSeatBeltCmd : 61|1@0+ (1,0) [0|1] "" IVI
 SG_ RCenterSeatBeltCmd : 62|1@0+ (1,0) [0|1] "" IVI
 SG_ TLHPsngrSeatBeltCmd : 63|1@0+ (1,0) [0|1] "" IVI
 SG_ TRHPsngrSeatBeltCmd : 48|1@0+ (1,0) [0|1] "" IVI
 SG_ CrashOutputSts : 47|8@0+ (1,0) [0|16] "" IVI
 SG_ LifeCount_ABM1 : 15|4@0+ (1,0) [0|15] "" Vector__XXX
 SG_ Checksum_ABM1 : 7|8@0+ (1,0) [0|255] "" Vector__XXX

BO_ 517 GW_SRR1: 8 FUSION
 SG_ SRR1_Chksum : 63|8@0+ (1,0) [0|255] "" IVI
 SG_ SRR_RCTA_WarnR : 48|1@0+ (1,0) [0|1] "" IVI
 SG_ SRR_RCTA_WarnL : 49|1@0+ (1,0) [0|1] "" IVI
 SG_ SRR_BSD_WarnR : 41|2@0+ (1,0) [0|3] "" IVI
 SG_ SRR_BSD_WarnL : 43|2@0+ (1,0) [0|3] "" IVI
 SG_ SRR_BSD_SoundR : 44|1@0+ (1,0) [0|1] "" IVI
 SG_ SRR_BSD_SoundL : 45|1@0+ (1,0) [0|1] "" IVI
 SG_ SRR_BSD_Mute : 46|1@0+ (1,0) [0|1] "" IVI
 SG_ SRR_ODA_WarnR : 33|2@0+ (1,0) [0|3] "" IVI
 SG_ SRR_ODA_WarnL : 35|2@0+ (1,0) [0|3] "" IVI
 SG_ SRR_ODA_SoundR : 36|1@0+ (1,0) [0|1] "" IVI
 SG_ SRR_ODA_SoundL : 37|1@0+ (1,0) [0|1] "" IVI
 SG_ SRR_ODA_Mute : 38|1@0+ (1,0) [0|1] "" IVI
 SG_ SRR_ODA_Sta : 18|3@0+ (1,0) [0|7] "" IVI
 SG_ SRR_BSD_Sta : 10|3@0+ (1,0) [0|7] "" IVI
 SG_ SRR_RCTA_Sta : 14|3@0+ (1,0) [0|7] "" IVI
 SG_ SRR_FltWrnReq : 15|1@0+ (1,0) [0|1] "" IVI
 SG_ SRR1_LifeCount : 7|4@0+ (1,0) [0|15] "" IVI

BO_ 528 FD_APS2: 32 FUSION
 SG_ PAS_A_FCL : 219|4@0+ (1,0) [0|15] "" IVI
 SG_ PAS_Chime : 223|4@0+ (1,0) [0|15] "" IVI
 SG_ APS_Progress_PCT : 215|8@0+ (1,0) [0|100] "%" Vector__XXX
 SG_ APS_RQ_Display : 207|8@0+ (1,0) [0|255] "" IVI
 SG_ PAS_D_RMR : 199|8@0+ (1,0) [0|150] "" IVI
 SG_ PAS_D_RML : 191|8@0+ (1,0) [0|150] "" IVI
 SG_ PAS_D_RCR : 183|8@0+ (1,0) [0|150] "" IVI
 SG_ PAS_D_RCL : 175|8@0+ (1,0) [0|150] "" IVI
 SG_ APS_SW_Ver : 167|8@0+ (1,0) [0|255] "" IVI
 SG_ APS_HW_Ver : 159|8@0+ (1,0) [0|255] "" Vector__XXX
 SG_ APS_ExitCondition : 151|8@0+ (1,0) [0|255] "" IVI
 SG_ PAS_D_FMR : 143|8@0+ (1,0) [0|150] "" IVI
 SG_ PAS_D_FML : 135|8@0+ (1,0) [0|150] "" IVI
 SG_ PAS_D_FCR : 127|8@0+ (1,0) [0|150] "" IVI
 SG_ PAS_D_FCL : 119|8@0+ (1,0) [0|150] "" IVI
 SG_ APS_D_RLR : 97|10@0+ (1,0) [0|1023] "" Vector__XXX
 SG_ APS_D_RLL : 81|10@0+ (1,0) [0|1023] "" Vector__XXX
 SG_ APS_D_FLR : 65|10@0+ (1,0) [0|1023] "" Vector__XXX
 SG_ APS_D_FLL : 49|10@0+ (1,0) [0|1023] "" Vector__XXX
 SG_ PAS_SNSR_Layout : 43|4@0+ (1,0) [0|15] "" IVI
 SG_ PAS_A_RMR : 47|4@0+ (1,0) [0|15] "" IVI
 SG_ PAS_A_RML : 35|4@0+ (1,0) [0|15] "" IVI
 SG_ PAS_A_RCR : 39|4@0+ (1,0) [0|15] "" IVI
 SG_ PAS_A_RCL : 27|4@0+ (1,0) [0|15] "" IVI
 SG_ PAS_A_FMR : 31|4@0+ (1,0) [0|15] "" IVI
 SG_ PAS_A_FML : 19|4@0+ (1,0) [0|15] "" IVI
 SG_ PAS_A_FCR : 23|4@0+ (1,0) [0|15] "" IVI
 SG_ PAS_Sta_F_Sys : 9|1@0+ (1,0) [0|1] "" Vector__XXX
 SG_ PAS_Mod_Operation : 11|2@0+ (1,0) [0|3] "" Vector__XXX
 SG_ USS_Sta_RMR : 12|1@0+ (1,0) [0|1] "" IVI
 SG_ USS_Sta_RML : 13|1@0+ (1,0) [0|1] "" IVI
 SG_ USS_Sta_RLR : 14|1@0+ (1,0) [0|1] "" IVI
 SG_ USS_Sta_RLL : 15|1@0+ (1,0) [0|1] "" IVI
 SG_ USS_Sta_RCR : 0|1@0+ (1,0) [0|1] "" IVI
 SG_ USS_Sta_RCL : 1|1@0+ (1,0) [0|1] "" IVI
 SG_ USS_Sta_FMR : 2|1@0+ (1,0) [0|1] "" IVI
 SG_ USS_Sta_FML : 3|1@0+ (1,0) [0|1] "" IVI
 SG_ USS_Sta_FLR : 4|1@0+ (1,0) [0|1] "" IVI
 SG_ USS_Sta_FLL : 5|1@0+ (1,0) [0|1] "" IVI
 SG_ USS_Sta_FCR : 6|1@0+ (1,0) [0|1] "" IVI
 SG_ USS_Sta_FCL : 7|1@0+ (1,0) [0|1] "" IVI
 SG_ FDC_VCU_RegenLimInd_Sta : 8|1@0+ (1,0) [0|1] "" IVI
 SG_ FDC_VCU_SmartEco_Sta : 51|1@0+ (1,0) [0|1] "" IVI
 SG_ FDC_VCU_SmartEcoSpdLim_Sta : 50|1@0+ (1,0) [0|1] "" IVI

BO_ 534 FD_BCM1: 16 FUSION
 SG_ DrDoorSW : 120|1@0+ (1,0) [0|1] "" IVI
 SG_ PsDoorSW : 121|1@0+ (1,0) [0|1] "" IVI
 SG_ RLDoorSW : 122|1@0+ (1,0) [0|1] "" IVI
 SG_ RRDoorSW : 123|1@0+ (1,0) [0|1] "" IVI
 SG_ AllDoorSW : 124|1@0+ (1,0) [0|1] "" IVI
 SG_ DoorLockIND : 125|1@0+ (1,0) [0|1] "" IVI
 SG_ HoodSW : 126|1@0+ (1,0) [0|1] "" IVI
 SG_ Tailgate_SW : 127|1@0+ (1,0) [0|1] "" IVI
 SG_ CTDCtrl : 113|2@0+ (1,0) [0|3] "" Vector__XXX
 SG_ Fr_ChargingDoorCtrl : 115|2@0+ (1,0) [0|3] "" Vector__XXX
 SG_ Rr_ChargingDoorCtrl : 117|2@0+ (1,0) [0|3] "" Vector__XXX
 SG_ CTDLockSW : 118|1@0+ (1,0) [0|1] "" Vector__XXX
 SG_ CTDUnlockSW : 119|1@0+ (1,0) [0|1] "" Vector__XXX
 SG_ MirrorDefog : 104|1@0+ (1,0) [0|1] "" Vector__XXX
 SG_ Rr_Defog : 105|1@0+ (1,0) [0|1] "" IVI
 SG_ TrunkRel : 106|1@0+ (1,0) [0|1] "" Vector__XXX
 SG_ TailgateHDSW : 107|1@0+ (1,0) [0|1] "" Vector__XXX
 SG_ MirrorCtrl : 109|2@0+ (1,0) [0|3] "" Vector__XXX
 SG_ Fr_Wiper_H : 110|1@0+ (1,0) [0|1] "" Vector__XXX
 SG_ Fr_Wiper_L : 111|1@0+ (1,0) [0|1] "" Vector__XXX
 SG_ Rr_Wiper : 96|1@0+ (1,0) [0|1] "" Vector__XXX
 SG_ WiperFixMode : 97|1@0+ (1,0) [0|1] "" Vector__XXX
 SG_ WasherCtrl : 99|2@0+ (1,0) [0|3] "" Vector__XXX
 SG_ L_Beam : 100|1@0+ (1,0) [0|1] "" IVI
 SG_ H_Beam : 101|1@0+ (1,0) [0|1] "" IVI
 SG_ PosLamp : 102|1@0+ (1,0) [0|1] "" IVI
 SG_ LDRL : 103|1@0+ (1,0) [0|1] "" IVI
 SG_ RDRL : 88|1@0+ (1,0) [0|1] "" IVI
 SG_ ReverseLamp : 89|1@0+ (1,0) [0|1] "" IVI
 SG_ BrakeLamp : 90|1@0+ (1,0) [0|1] "" IVI
 SG_ LBSD : 91|1@0+ (1,0) [0|1] "" IVI
 SG_ RBSD : 92|1@0+ (1,0) [0|1] "" IVI
 SG_ Fr_FogLamp : 93|1@0+ (1,0) [0|1] "" IVI
 SG_ Rr_FogLamp : 94|1@0+ (1,0) [0|1] "" IVI
 SG_ HazardSW : 95|1@0+ (1,0) [0|1] "" IVI
 SG_ LTurnLP : 80|1@0+ (1,0) [0|1] "" IVI
 SG_ RTurnLP : 81|1@0+ (1,0) [0|1] "" IVI
 SG_ AntitheftSta : 83|2@0+ (1,0) [0|3] "" IVI
 SG_ AntiTheftSeatFold : 84|1@0+ (1,0) [0|1] "" Vector__XXX
 SG_ CrashDetd : 85|1@0+ (1,0) [0|1] "" Vector__XXX
 SG_ L_APM_WdwEnable : 87|1@0+ (1,0) [0|1] "" Vector__XXX
 SG_ Dimmer : 78|7@0+ (1,0) [0|100] "%" IVI
 SG_ LockSetting : 79|1@0+ (1,0) [0|1] "" IVI
 SG_ BCM_Buzzer_Req : 64|1@0+ (1,0) [0|1] "" Vector__XXX
 SG_ TailgateRemote : 66|2@0+ (1,0) [0|3] "" Vector__XXX
 SG_ RoomLampL : 67|1@0+ (1,0) [0|1] "" Vector__XXX
 SG_ RoomLampH : 68|1@0+ (1,0) [0|1] "" Vector__XXX
 SG_ DimmerEN : 69|1@0+ (1,0) [0|1] "" Vector__XXX
 SG_ BCM_DoorLock_Sta : 70|1@0+ (1,0) [0|1] "" IVI
 SG_ HornCtrl : 71|1@0+ (1,0) [0|1] "" Vector__XXX
 SG_ FollowMe : 86|1@0+ (1,0) [0|1] "" IVI
 SG_ APMDoorControlSta : 63|1@0+ (1,0) [0|1] "" IVI
 SG_ FDC_BCM_LockAlarm_Cmd : 62|2@0+ (1,0) [0|2] "" IVI
 SG_ FDC_THCM_APTCWarning_Sta : 60|1@0+ (1,0) [0|1] "" IVI

CM_ SG_ 278 XWDMode "Driving Wheel Selection Mode (RWD/FWD/AWD)";
CM_ SG_ 278 PwrSta "Vehicle Power Status";
CM_ SG_ 278 DCDCVoltSetpoint "DCDC voltage setpoint  request";
CM_ SG_ 278 DCDCEnaReq "DCDC Enable Request";
CM_ SG_ 278 Fr_MCUEnaReq "Front MCU Enable Request";
CM_ SG_ 278 Rr_MCUEnaReq "Rear MCU Enable Request";
CM_ SG_ 278 HVBatCnctReq "HV Battery Pack Connect Request";
CM_ SG_ 278 ActiveDischReq "System Active Discharge Request";
CM_ SG_ 278 PrkReq "Parking Request";
CM_ SG_ 278 Fr_ActvDmpDisabReq "Front EDU Low Speed Active Damping Disable Request";
CM_ SG_ 278 Rr_ActvDmpDisabReq "Rear EDU Low Speed Active Damping Disable Request";
CM_ SG_ 278 HVSysReadyToCharge "To notify OBC if EV system is ready to be charged during plugin situation.";
CM_ SG_ 278 ShiftGearPosn "EV Selector Position Status/ Selector Position Status Signal Failure";
CM_ SG_ 278 LVChrgFuncStaChk "Silent charging function state check";
CM_ SG_ 278 CC_Crl_Sta "Cruise Control Status";
CM_ SG_ 278 MSA_Crl_Sta "MSA Status";
CM_ SG_ 278 DemoModeStaChk "Demo mode state check";
CM_ SG_ 278 CoastDwModeStaChk "Coastdown mode state check";
CM_ SG_ 278 DynoModeStaChk "Dyno mode state check";
CM_ SG_ 278 Dr_SeatSta "Driver seat switch state";
CM_ SG_ 278 FalseNPrevent_Sta "False N prevention state";
CM_ SG_ 278 DisengageP_Fail "disengage P gear failure";
CM_ SG_ 278 EngageP_Fail "engage P gear failure";
CM_ SG_ 278 CreepSW_Sta "creep switch state";
CM_ SG_ 278 RC_VCU1_CAN2 "VCU1 4-bit rolling counter";
CM_ SG_ 278 CS_VCU1_CAN2 "VCU1 frame checksum 
x^8+x^4+x^3+x^2+1 
It shall use 0xFF as the start value and XOR value.";
CM_ SG_ 278 VCU_OPDHold "One-pedal Brake Hold";
CM_ SG_ 278 FDC_VCU_PwrSaveReq_Cmd "VCU power save request";
CM_ SG_ 338 RearAxlTrqReq_Drv "Rear Axle DrivingTorque Limitation";
CM_ SG_ 338 FrntAxlTrqReq_Drv "Front Axle Driving Torque Limitation";
CM_ SG_ 338 VehSpeed "Vehicle Speed";
CM_ SG_ 338 Fr_PTCS_Active "Front Axle Torque Reduction Active";
CM_ SG_ 338 Rr_PTCS_Active "Rear Axle Torque Reduction Active";
CM_ SG_ 338 ESC1_RC "Rolling Counter of ESC1";
CM_ SG_ 338 ESC1_CS "Checksum of ESC1

complement = ((Sigma(first 15 halfbytes) + 2) XOR 0xFF)Checksum = complement MOD 0x10";
CM_ SG_ 360 LowBrakeFluid_Sta "Low Brake Fluid Status";
CM_ SG_ 360 eBST_AmberWnlmpSta "eBST Amber Warning Lamp Status";
CM_ SG_ 360 eBST_RedWnlmpSta "eBST Red Warning Lamp Status";
CM_ SG_ 360 eBST_BeepReq "eBST Beep Sound Request";
CM_ SG_ 369 HVBPwrAvailChrg30 "HV battery available charging power 30 second";
CM_ SG_ 369 HVBPwrAvailDchrg30 "HV battery available discharge power 30 second";
CM_ SG_ 369 HVBPwrAvailChrg "HV battery available charging power";
CM_ SG_ 369 HVBPwrAvailDchrg "HV battery available discharge power";
CM_ SG_ 369 HVBPwrAvailChrg60 "HV battery available charging power 60 second";
CM_ SG_ 369 HVBPwrAvailDchrg60 "HV battery available discharge power 60 second";
CM_ SG_ 369 HVBattCurr "HV battery pack current";
CM_ SG_ 369 HVBattVolt "HV battery pack Volt";
CM_ SG_ 369 BMSRolCnct_1 "BMS RollingCount";
CM_ SG_ 369 BMSChckSum_1 "BMS CheckSum";
CM_ SG_ 377 FCM2_Checksum "The [CAN CheckSum] shall be calculated as a CRC8 with the following polynomial: x^8+x^4+x^3+x^2+1 (=0x1D), according with SAE-J1850-CRC8 Start value 0xFF";
CM_ SG_ 377 ACC_ComfortBandLower "Required acceleration lower limit - Comfort";
CM_ SG_ 377 ACC_JerkLowerLimit "Jerk lower limit - Jerk";
CM_ SG_ 377 ACC_ComfortBandUpper "Required acceleration upper limit - Comfort";
CM_ SG_ 377 ACC_JerkUpperLimit "Jerk upper limit - Jerk";
CM_ SG_ 377 ACC_RequiredAccel "Required acceleration";
CM_ SG_ 377 ADAS_AEBReq "AEB Request";
CM_ SG_ 377 FCM2_LifeCount "Rolling Counter of FCM2";
CM_ SG_ 377 ADAS_FaultSta "ADAS Fault Status";
CM_ SG_ 377 AEB_VehHoldReq "Vehicle Hold Request";
CM_ SG_ 377 ADAS_DBSReq "DBS request to ESC";
CM_ SG_ 377 ACC_VehHoldReq "ACC Hold Request";
CM_ SG_ 378 BMS_Warn_1 "BMS Warning1";
CM_ SG_ 378 BMS_Warn_2 "BMS Warning2";
CM_ SG_ 378 BMS_Warn_3 "BMS Warning3";
CM_ SG_ 378 BMS_Warn_4 "BMS Warning4";
CM_ SG_ 378 BMS_Warn_5 "BMS Warning5";
CM_ SG_ 378 BMS_Warn_6 "BMS Warning6";
CM_ SG_ 378 BMS_Warn_7 "BMS Warning7";
CM_ SG_ 378 BMS_Warn_8 "BMS Warning8";
CM_ SG_ 378 HVBOvrTempWarn "Over temperature warn";
CM_ SG_ 378 HVBUndrTempWarn "Under temperature warn";
CM_ SG_ 378 HVBOvrVoltErr "Pack over Volt";
CM_ SG_ 378 HVBUndrVoltErr "Pack under Volt";
CM_ SG_ 378 HVBShrtChrgCurrErr "Short charge current";
CM_ SG_ 378 HVBShrtDischrgCurrErr "Short discharge current";
CM_ SG_ 378 HVBOvrChrgCurrErr "Over charge current";
CM_ SG_ 378 HVBOvrDchrgCurErr "Over discharge current";
CM_ SG_ 378 HVBOvrTempErr "Over temperature";
CM_ SG_ 378 HVBUndrTempErr "Under temperature";
CM_ SG_ 378 HVBOvrSOCErr "Over SOC";
CM_ SG_ 378 HVBUndrSOCErr "Under SOC";
CM_ SG_ 378 HVBSOCJumpError "SOC Jump Error";
CM_ SG_ 378 HVBHVILErr "HVIL hardware failed";
CM_ SG_ 378 DCChrgSysShockErr "DC Charge System Shock Error";
CM_ SG_ 378 BMS_READY "BMS ready";
CM_ SG_ 378 HVBContactorSta "HV battery contactor closed status";
CM_ SG_ 378 HVBPrechrgSta "BMS informs VCU HV battery precharge status";
CM_ SG_ 378 HVBTempDiffErr "Temperature Different Error";
CM_ SG_ 378 HVILSta "HVIL status";
CM_ SG_ 378 HVBattReady4Pre "BMS informs VCU HV battery is ready to be Precharged";
CM_ SG_ 378 ChrgPlugSta "Charger plug status";
CM_ SG_ 378 ExtChrgSta "External charging status";
CM_ SG_ 378 HVBPreheatPrecoolSta "BMS informs VCU HV battery is over heat or cold";
CM_ SG_ 378 IsoDetSta "Isolation Detection status. Send every 100ms and event trigger, especially power down";
CM_ SG_ 378 SystemUncomErr "System Uncompitable Error";
CM_ SG_ 378 CellUnconsistErr "Cell Unconsistency Error";
CM_ SG_ 378 HVBCellOvrVoltWarn "Cell over Volt warn";
CM_ SG_ 378 HVBCellUdrVoltWarn "Cell under Volt warn";
CM_ SG_ 378 HVBCellOvrVoltErr "Cell over Volt";
CM_ SG_ 378 HVBCellUndrVoltErr "Cell under Volt";
CM_ SG_ 378 HVBCellUnbalanErr "Cell unbalance";
CM_ SG_ 378 ChrgInLockReq "ChargeInlet Lock Request";
CM_ SG_ 378 DisChrgPlugErr "(Dis)Charger plug Error
0x0 : Normal
0x1 : plug-in incomplete
0x2 : (un)lock request invalid";
CM_ SG_ 378 HVBChrgErr "HVB Charge Error";
CM_ SG_ 378 V2LSta "V2L Adapter Status";
CM_ SG_ 378 BMSRolCnct "BMS RollingCount";
CM_ SG_ 378 BMSChckSum "BMS CheckSum";
CM_ SG_ 380 FCM3_Checksum "The [CAN CheckSum] shall be calculated as a CRC8 with the following polynomial: x^8+x^4+x^3+x^2+1 (=0x1D), according with SAE-J1850-CRC8 Start value 0xFF";
CM_ SG_ 380 ACC_ObjRelSpd "Object relative speed";
CM_ SG_ 380 ADAS_ForceIdle "Forced Idle";
CM_ SG_ 380 FCM3_LifeCount "Rolling Counter of FCM3";
CM_ SG_ 380 ACC_ObjDist "Object distance";
CM_ SG_ 380 ADAS_ShftPosnReq "Shifter Position Request";
CM_ SG_ 380 ADAS_ShftPosnReq_A "Shifter Position Request Applicable";
CM_ SG_ 380 ADAS_VehSpdLim "Vehicle Speed Limit(if Distance_unit = 0x0, then UNIT = km/h, else  UNIT = mph)";
CM_ SG_ 383 CCMSA_SpdWar "CC/MSA downslope overspeed warning";
CM_ SG_ 386 Rr_Coolanttemp "LLC coolant temp";
CM_ SG_ 386 Rr_Coolantflow "LLC coolant flow rate";
CM_ SG_ 386 FD_AGS_Cmd "Fusion Domain AGS Position Request";
CM_ SG_ 386 sigClntTHvBattOut "battery coolant outlet temperature";
CM_ SG_ 386 sigCbnSolarLeft "Measured cabin sun exposure";
CM_ SG_ 386 CabinMode "Cabin Mode";
CM_ SG_ 386 BatteryMode "Battery Mode";
CM_ SG_ 386 FD_RecyAuto_Cmd "Auto recycle command";
CM_ SG_ 386 sigCbnSolarRight "Measured cabin sun exposure";
CM_ SG_ 386 sigAmbAirT "Environment temperature (outside ambient vehicle temperature)";
CM_ SG_ 386 sigCbnAirT "Cabin air temperature";
CM_ SG_ 386 sigCbnPTCPwrAct "Current power consumption FRONT AirPTC";
CM_ SG_ 386 sigClmtCmprPwrAct "Current power consumption AC compressor";
CM_ SG_ 386 Fr_Coolantflow "LLC coolant flow rate";
CM_ SG_ 386 EDriveMode "E-Drive Mode";
CM_ SG_ 386 sigSetTempZon1St "Feedback: Temperature set in the HVAC for Zone 1";
CM_ SG_ 386 HPThermalRecoveryReq "Heat Pump thermal reuse request";
CM_ SG_ 386 sigSetTempZon2St "Feedback: Temperature set in the HVAC for Zone 2";
CM_ SG_ 386 sigHvacSt "Status of the HVAC (ON / OFF)";
CM_ SG_ 386 sigRecircSt "Recirculation Status in the HVAC (Fre/Rec/Auto)";
CM_ SG_ 386 sigSetTempZon3St "Feedback: Temperature set in the HVAC for Zone 3";
CM_ SG_ 386 sigDfrstSt "Defrost Status in the HVAC (ON / AUTO)";
CM_ SG_ 386 CCU_SyncLampSts "Climate SYNC lamp state";
CM_ SG_ 386 sigAirIntenZon3St "Feedback FAN Level/Air Intensirty : 0-Max or Auto for zone 3";
CM_ SG_ 386 sigAirIntenZon1St "Feedback FAN Level/Air Intensirty : 0-Max or Auto for zone 1";
CM_ SG_ 386 sigWindDirZon3St "Feedback: WInd DirectionZone 3. 
Feed, Body and/or Auto";
CM_ SG_ 386 CCU_FrtOnOffLampSts "Front Climate On Off lamp state";
CM_ SG_ 386 sigWindDirZon1St "Feedback: WInd DirectionZone 1. 
Feed, Body, WIndscreen and/or Auto";
CM_ SG_ 386 CCU_RrOnOffLampSts "Rear Climate On Off lamp state";
CM_ SG_ 386 Fr_Coolanttemp "LLC coolant temp";
CM_ SG_ 386 CCU_ACMaxLampSts "Climate AC Max lamp state";
CM_ SG_ 386 CCU_AutoLampSts "Climate air conditionning Front  automatic mode lamp state";
CM_ SG_ 386 CCU_AutoMidLampSts "Climate air conditionning middle left automatic mode lamp state";
CM_ SG_ 386 CCU_EcoSts "Economic mode status";
CM_ SG_ 386 CCU_Dispaly_Request "Air Conditioner display reuqest trigger";
CM_ SG_ 386 CCU_ACLampSts "Climate AC lamp state";
CM_ SG_ 386 CCU_HEATMaxLampSts "Climate HEATING Max lamp state";
CM_ SG_ 389 CS_CCU1 "CCU1 frame checksum";
CM_ SG_ 389 DCDCAuxVolt "DC/DC Output Volt";
CM_ SG_ 389 RC_CCU1 "CCU1 4-bit rolling counter";
CM_ SG_ 389 DCDCInVoltInf "DC/DC Input Voltage Information";
CM_ SG_ 389 DCDCPreCompleted "DCDC Precharge Completed";
CM_ SG_ 389 OBCPreCompleted "OBC Precharge Completed";
CM_ SG_ 389 OBCDCCurrInf "OBC DC Current Information";
CM_ SG_ 389 OBCWakeup4Plugin "OBC Wake Up For Plugin";
CM_ SG_ 389 OBCDCVoltInf "OBC DC Voltage Information";
CM_ SG_ 395 DCDCAuxCur "DC/DC Output Current";
CM_ SG_ 395 DCDCHVCur "DC/DC Input Current";
CM_ SG_ 395 OBCV2LVinUVP "OBC V2L INPUT UVP";
CM_ SG_ 395 OBCV2LVinOVP "OBC V2L INPUT OVP";
CM_ SG_ 395 OBCV2LINVOTP "OBC V2L INVERTER OTP";
CM_ SG_ 395 OBCV2LInsuFault "OBC V2L Insulation Fault";
CM_ SG_ 395 OBCV2LVoutOCP "OBC V2L OUTPUT OCP";
CM_ SG_ 395 OBCV2LVoutOVP "OBC V2L OUTPUT OVP";
CM_ SG_ 395 OBCV2LVoutUVP "OBC V2L OUTPUT UVP";
CM_ SG_ 402 Rr_EDUTqReqFbk "Rear EDU Torque Request Feedback";
CM_ SG_ 402 Rr_MCUEnaSta "Rear MCU Enable Status";
CM_ SG_ 402 Rr_EDUOpratingSta "Rear EDU Torque/Speed Status";
CM_ SG_ 402 Rr_EDURotateDirction "Rear EDU Direction Status";
CM_ SG_ 402 Rr_EDURealTMTq "Rear EDU Real Torque from TM";
CM_ SG_ 402 Rr_TMSpd "Rear TM speed";
CM_ SG_ 402 Rr_MCUReady4Pre "Rear MCU Ready for Precharge";
CM_ SG_ 402 Rr_ActvDmpDisabSta "Rear MCU Low speed active damping disable status";
CM_ SG_ 402 Rr_EDUDrtSta "Rear EDU Torque Derating Status";
CM_ SG_ 402 Rr_MCUDischrgSta "Rear MCU Discharge Status";
CM_ SG_ 402 Rr_MCUReady "Rear MCU Ready";
CM_ SG_ 402 Rr_MCUDCBusVolt "Rear MCU DC-Bus Voltage";
CM_ SG_ 402 Rr_MCUDCBusCurr "Rear  MCU DC Current";
CM_ SG_ 402 Rr_MCUTemp "Rear  MCU Temperature";
CM_ SG_ 402 Rr_TMTemp "Rear  TM Temperature";
CM_ SG_ 402 Rr_MCUErr "Rear  MCU Error Code";
CM_ SG_ 402 Rr_TMid "Rear  TM id Feedback";
CM_ SG_ 402 Rr_TMiq "Rear  TM iq Feedback";
CM_ SG_ 402 Rr_MotorAvailTq "Rear Motor Torque Available";
CM_ SG_ 402 Rr_RegenAvailTq "Rear RegenerationTorque Available";
CM_ SG_ 402 Rr_MCUIGN_sta "IGN ON/OFF Status";
CM_ SG_ 402 Rr_Reserved_bits "Rear  Reserved bits";
CM_ SG_ 402 Rr_MCUBAT "Rear  Bat Voltage";
CM_ SG_ 402 Rr_MCUSysSta "Rear MCU System Status";
CM_ SG_ 402 MCUWarn_R "MCU warning signal_Rear";
CM_ SG_ 402 Rr_MCU1RolCnt "Rear  MCU1 4 bits Process counter";
CM_ SG_ 402 Rr_MCU1Chksum "Rear  MCU1 Frame checksum(SAEJ1850) 
x^8+x^4+x^3+x^2+1
It shall use 0xFF as the start value and XOR value.";
CM_ SG_ 406 Fr_EDUTqReqFbk "Front EDU Torque Request Feedback";
CM_ SG_ 406 Fr_MCUEnaSta "Front MCU Enable Status";
CM_ SG_ 406 Fr_EDUOpratingSta "Front EDU Torque/Speed Status";
CM_ SG_ 406 Fr_EDURotateDirction "Front EDU Direction Status";
CM_ SG_ 406 Fr_EDURealTMTq "Front EDU Real Torque from TM";
CM_ SG_ 406 Fr_TMSpd "Front TM speed";
CM_ SG_ 406 Fr_MCUReady4Pre "Front MCU Ready for Precharge";
CM_ SG_ 406 Fr_ActvDmpDisabSta "Front MCU Low speed active damping disable status";
CM_ SG_ 406 Fr_EDUDrtSta "Front EDU Torque Derating Status";
CM_ SG_ 406 Fr_MCUDischrgSta "Front MCU Discharge Status";
CM_ SG_ 406 Fr_MCUDCBusVolt "Front MCU DC-Bus Voltage";
CM_ SG_ 406 Fr_MCUDCBusCurr "Front MCU DC Current";
CM_ SG_ 406 Fr_MCUTemp "Front MCU Temperature";
CM_ SG_ 406 Fr_TMTemp "Front TM Temperature";
CM_ SG_ 406 Fr_MCUErr "Front MCU Error Code";
CM_ SG_ 406 Fr_TMid "Front TM id Feedback";
CM_ SG_ 406 Fr_TMiq "Front TM iq Feedback";
CM_ SG_ 406 Fr_MotorAvailTq "Front Motor Torque Available";
CM_ SG_ 406 Fr_RegenAvailTq "Front RegenerationTorque Available";
CM_ SG_ 406 Fr_MCUIGN_sta "IGN ON/OFF Status";
CM_ SG_ 406 Fr_Reserved_bits "Front Reserved bits";
CM_ SG_ 406 Fr_MCUBAT "Front Bat Voltage";
CM_ SG_ 406 Fr_MCUSysSta "Front MCU System Status";
CM_ SG_ 406 MCUWarn_F "MCU warning signal_Front";
CM_ SG_ 406 Fr_MCUReady "Front MCU Ready";
CM_ SG_ 406 Fr_MCU1RolCnt "Front MCU1 4 bits Process counter";
CM_ SG_ 406 Fr_MCU1Chksum "Front MCU1 Frame checksum(SAEJ1850) 
x^8+x^4+x^3+x^2+1
It shall use 0xFF as the start value and XOR value.";
CM_ SG_ 408 Fr_LLCTemp "Front LLC temperature";
CM_ SG_ 408 Fr_LLCflowReq "Front request LLC flow rate";
CM_ SG_ 408 Fr_EOP_SpdSet "Front MCU request EOP Speed";
CM_ SG_ 408 Fr_Failcode1 "Front Detail fail code";
CM_ SG_ 408 Fr_Failcode2 "Front Detail fail code";
CM_ SG_ 408 Fr_Failcodehistory1 "Front Failcode history status";
CM_ SG_ 408 Fr_Failcodehistory2 "Front Failcode history status";
CM_ SG_ 408 Fr_TMTempWarn "FrontTM Temperature Warning";
CM_ SG_ 408 Fr_MCUTempWarn "Front MCU Temperature Warning";
CM_ SG_ 408 Fr_CoolanttempReq "LLC coolant temp Request";
CM_ SG_ 408 Fr_MCU2RolCnt "Front MCU2 4bits Process counter";
CM_ SG_ 408 Fr_MCU2Chksum "Front MCU2 Frame checksum(SAEJ1850) 
x^8+x^4+x^3+x^2+1
It shall use 0xFF as the start value and XOR value.";
CM_ SG_ 408 MCU_F_ResetCnt_Sta "Front  MCU Reset counter";
CM_ SG_ 410 SAS_Angle "Absoluted Steering Wheel Angle
(Positive value is clockwise.
When not being calibrated, invalid = 'FFFFh')";
CM_ SG_ 410 SAS_Speed "Steering Wheel rotation speed
(When not being, calibrated, this value = '0')";
CM_ SG_ 410 SAS_Speed_Valid "Steering Wheel rotation speed validity";
CM_ SG_ 410 SAS_CAL "SAS Calibrated Status";
CM_ SG_ 410 SAS_V "Steering Wheel Angle validity ( Status of Senosr Failure)";
CM_ SG_ 410 SAS_MsgCount "Number of the Message";
CM_ SG_ 410 SAS_CheckSum "SAS Checksum of all bytes of the CAN matrix";
CM_ SG_ 412 Rr_LLCTemp "Rear  LLC temperature";
CM_ SG_ 412 Rr_LLCflowReq "Rear  request LLC flow rate";
CM_ SG_ 412 Rr_EOP_SpdSet "Rear  MCU request EOP Speed";
CM_ SG_ 412 Rr_Failcode1 "Rear  Detail fail code";
CM_ SG_ 412 Rr_Failcode2 "Rear  Detail fail code";
CM_ SG_ 412 Rr_Failcodehistory1 "Rear  Failcode history status";
CM_ SG_ 412 Rr_Failcodehistory2 "Rear Failcode history status";
CM_ SG_ 412 Rr_TMTempWarn "Rear TM Temperature Warning";
CM_ SG_ 412 Rr_MCUTempWarn "Rear MCU Temperature Warning";
CM_ SG_ 412 Rr_CoolanttempReq "LLC coolant temp Request";
CM_ SG_ 412 Rr_MCU2RolCnt "Rear MCU2 4bits Process counter";
CM_ SG_ 412 Rr_MCU2Chksum "Rear  MCU2 Frame checksum(SAEJ1850) 
x^8+x^4+x^3+x^2+1
It shall use 0xFF as the start value and XOR value.";
CM_ SG_ 412 MCU_R_ResetCnt_Sta "Rear MCU Reset counter";
CM_ SG_ 419 Red_WnlmpSta "Red Warning Lamp Status";
CM_ SG_ 419 ABS_WnlmpSta "ABS Warning Lamp Status";
CM_ SG_ 419 ESC_Off_lmpSta "ESC Off Warning Lamp Status";
CM_ SG_ 419 ESC_WnlmpSta "ESC Warning Lamp Status";
CM_ SG_ 419 GRADE "Surface Grade(dynamic)";
CM_ SG_ 419 EBD_Active "EBD System Active";
CM_ SG_ 419 ABS_Active "Antilock Brake System Active";
CM_ SG_ 419 TCS_Active "Traction Control System Active";
CM_ SG_ 419 ESC_Active "Electronic Stability Control Active";
CM_ SG_ 419 HBB_Active "Hydraulic Brake Boost Active";
CM_ SG_ 419 PBA_Active "Panic Brake Assist Active";
CM_ SG_ 419 HSA_Active "Hill Start Assist Active";
CM_ SG_ 419 AVH_Active "Auto Hold Active";
CM_ SG_ 419 Amber_WnlmpSta "Amber Warning Lamp Status";
CM_ SG_ 419 BTCS_Active "Brake Traction Control System Active";
CM_ SG_ 419 ESS_Active "Emergency Stop Signaling Active";
CM_ SG_ 419 HDD_Active "Hydraulic Dynamic Deceleration Active";
CM_ SG_ 419 EBD_Failed "EBD System Failed";
CM_ SG_ 419 ABS_Failed "Antilock Brake System Failed";
CM_ SG_ 419 TCS_Failed "Traction Control System Failed";
CM_ SG_ 419 ESC_Failed "Electronic Stability Control Failed";
CM_ SG_ 419 HBB_Failed "Hydraulic Brake Boost Failed";
CM_ SG_ 419 PBA_Failed "Panic Brake Assist Failed";
CM_ SG_ 419 HSA_Failed "Hill Start Assist Failed";
CM_ SG_ 419 AVH_Failed "Auto Hold Failed";
CM_ SG_ 419 HDD_Failed "Hydraulic Dynamic Deceleration Failed";
CM_ SG_ 419 ESC_OFF_Status "Electronic Stability Control OFF Status";
CM_ SG_ 419 ESC_BeepReq "ESC Beep Sound Request";
CM_ SG_ 419 SystemVoltage "Battery Voltage";
CM_ SG_ 421 YawRate "Yaw Rate";
CM_ SG_ 421 LatAccel "Lateral Acceleration";
CM_ SG_ 421 LongAccel "Longitudinal Acceleration";
CM_ SG_ 421 MCPressure "Master Cylinder Pressure";
CM_ SG_ 421 ESC5_RC "Rolling Counter of ESC5";
CM_ SG_ 421 ESC5_CRC8 "Checksum of ESC5 (SAE-J1850-CRC8)";
CM_ SG_ 421 YawRate_V "Yaw Rate Validity";
CM_ SG_ 421 LatAccel_V "Lateral Acceleration Validity";
CM_ SG_ 421 LongAccel_V "Longitudinal Acceleration Validity";
CM_ SG_ 421 MCPressure_V "Master Cylinder Pressure Validity";
CM_ SG_ 421 BrkSw_Sta "Brake switch signal status";
CM_ SG_ 421 BrkSw_V "Brake switch signal Vaild";
CM_ SG_ 425 Meter_Ind_VehSpeed "Meter Indicated Vehicle Speed";
CM_ SG_ 425 ACCAvail "ACC Availability";
CM_ SG_ 425 BrkDiscTempSta "Brake Disc Temperature Status";
CM_ SG_ 425 ESC_Standstill "Standstill Status for APS";
CM_ SG_ 425 DecErrSta "Deceleration Error Status";
CM_ SG_ 425 ActBrkLamp_Sta "Active Brake Lamp Status";
CM_ SG_ 425 AEBAvail "AEB Availability";
CM_ SG_ 425 ESC_ADAS_Sta "Resopnse Status to ADAS Request";
CM_ SG_ 425 ESC_APS_Sta "Response Status to APS Request";
CM_ SG_ 425 ESC6_RC "Rolling Counter of ESC6";
CM_ SG_ 425 ESC6_CS "Checksum of ESC6

complement = ((Sigma(first 15 halfbytes) + 2) XOR 0xFF)Checksum = complement MOD 0x10";
CM_ SG_ 427 EPBExtReleaseAvail "EPB External Release Availability";
CM_ SG_ 427 EPBExtApplyAvail "EPB External Control Availability";
CM_ SG_ 427 EPBCarWashMode "EPB Car Wash Mode";
CM_ SG_ 427 DOA_Sta "Door Open Apply Status";
CM_ SG_ 427 EPBStaL "Electric Parking Brake Status Left";
CM_ SG_ 427 TakeOverReq "Backup EPB Take Over Request";
CM_ SG_ 427 EPBStaR "Electric Parking Brake Status Right";
CM_ SG_ 427 EPBErrSta "EPB Error Status";
CM_ SG_ 427 EPBRLampSta "EPB Red Lamp Status";
CM_ SG_ 427 EPBSta "Electric Parking Brake Status";
CM_ SG_ 427 EPBMsg "EPB Message";
CM_ SG_ 427 EPB1_RC "Rolling Counter of EPB1";
CM_ SG_ 427 EPB1_CS "Checksum of EPB1

complement = ((£U(first 15 halfbytes) + 2) XOR 0xFF)Checksum = complement MOD 0x10";
CM_ SG_ 470 OBCFaultSta "OBC Fault Status";
CM_ SG_ 470 DCDCFaultSta "DCDC Fault Status";
CM_ SG_ 470 OBCReady4Pre "OBC Ready For Precharge";
CM_ SG_ 470 DCDCReady4Pre "DCDC Converter Ready For Precharge";
CM_ SG_ 470 OBCTemp "OBC Temperature";
CM_ SG_ 470 DCDCTemp "DC/DC Temperature";
CM_ SG_ 470 OBCDCP "OBC DC Power";
CM_ SG_ 470 DCDCEnaSta "DCDC status: HV operation enabled/disabled";
CM_ SG_ 470 OBCPluginSta "OBC Plugin Status";
CM_ SG_ 470 OBCEnaSta "Current Enable Status of OBC";
CM_ SG_ 470 OBCACCurrInf "OBC AC Current Information";
CM_ SG_ 470 OBCACVoltInf "OBC AC Voltage Information";
CM_ SG_ 470 OBC_AC_Cur_Lim "OBC AC Current Limit";
CM_ SG_ 470 OBCV2LSta "OBC V2L Status";
CM_ SG_ 470 ReqOBCV2LEna "Request OBC V2L Enable";
CM_ SG_ 470 RC_CCU2 "CCU2 4-bit rolling counter";
CM_ SG_ 470 CS_CCU2 "CCU2 frame checksum";
CM_ SG_ 497 DrPowerTemp2 "Detect temperature on ZONE power board";
CM_ SG_ 497 DrPowerTemp1 "Detect temperature on ZONE power board";
CM_ SG_ 497 DrCtrlTemp "Detect temperature on ZONE Ctrl board";
CM_ SG_ 497 DrCtrlBDVolt "Detect voltage on ZONE Ctrl board";
CM_ SG_ 497 DrPwrONA1Curr "Zone Dr 'Power_ON_A1' pin electric current";
CM_ SG_ 497 DrPwrONA2Curr "Zone Dr 'Power_ON_A2' pin electric current";
CM_ SG_ 497 DrPwrStdbyACurr "Zone Dr 'Power_Standby_A' pin electric current";
CM_ SG_ 497 DrAuBoxPwrN1Curr "Zone Dr 'AUDIO BOX POWER NODE1' pin electric current";
CM_ SG_ 497 DrAuBoxPwrN2Curr "Zone Dr 'AUDIO BOX POWER NODE2' pin electric current";
CM_ SG_ 497 DrColumnSWFault "Zone Dr 'ColumnSW' pin fault state";
CM_ SG_ 497 DrTHCMFault "Zone Dr 'THCM' pin fault state";
CM_ SG_ 497 DrPwrWindowECUFault "Zone Dr 'Power_Window_ECU' pin fault state";
CM_ SG_ 497 DrInfoFault "Zone Dr 'Information' pin pin fault state";
CM_ SG_ 497 DrEOBDFault "Zone Dr 'EOBD' pin fault state";
CM_ SG_ 497 DrIVIFault "Zone Dr 'IVI' pin fault state";
CM_ SG_ 497 DrPMMLimpHomeActReq "PMM Limp Home act request";
CM_ SG_ 497 DrPMMLVOutPErrLmp "PMM LV output error lamp request";
CM_ SG_ 497 DrPMMSysErrLmp "PMM system error lamp request";
CM_ SG_ 497 DrPwrSta "DR PwrSta transmit";
CM_ SG_ 497 DrPwrInformationSta "Information pin B+ power request status";
CM_ SG_ 497 ZDR_SYS_APMRetryCnt_Sta "Zone DR APM power output pin retry count";
CM_ SG_ 497 ZDR_SYS_CSWRetryCnt_Sta "Zone DR ColumnSW power output pin retry count";
CM_ SG_ 497 ZDR_SYS_BSWSleepReq_Sta "Zone DR sleep request from BSW";
CM_ SG_ 497 DrAPWLINErr "APW LIN lost communication";
CM_ SG_ 497 DrAPWStaErr "APW relay error state";
CM_ SG_ 497 DrONA1ErrSta "Zone Dr power ON A1 power pin error state";
CM_ SG_ 497 DrPwrWinErrSta "Zone Dr power window power pin error  state";
CM_ SG_ 497 DrStdAErrSta "Zone Dr power standby A power pin error  state";
CM_ SG_ 497 DrInfoErrSta "Zone Dr information power pin error  state";
CM_ SG_ 497 ZoneDrMalfunLevel "Zone Dr VCU error level";
CM_ SG_ 497 ZDR_VCU_HWReset_Sta "Zone Dr VCU hardware reset state";
CM_ SG_ 497 ZDR_VCU_PwrSupply_Sta "Zone Dr VCU power supply state";
CM_ SG_ 498 FrPowerTemp1 "Detect temperature on ZONE power board";
CM_ SG_ 498 FrPowerTemp2 "Detect temperature on ZONE power board";
CM_ SG_ 498 FrCtrlTemp "Detect temperature on ZONE Ctrl board";
CM_ SG_ 498 FrCtrlBDVolt "Detect voltage on ZONE Ctrl board";
CM_ SG_ 498 FrPwrStdbyA1PlusCurr "Zone Fr 'Power_Standby_A1+' pin electric current";
CM_ SG_ 498 FrIRC_2Curr "Zone Fr 'IRC_2' pin electric current";
CM_ SG_ 498 FrPwrONA2Curr "Zone Fr 'Power_ON_A2' pin electric current";
CM_ SG_ 498 FrPwrONA3Curr "Zone Fr 'Power_ON_A3' pin electric current";
CM_ SG_ 498 FrPwrStdbyA2Curr "Zone Fr 'Power_Standby_A2' pin electric current";
CM_ SG_ 498 FrIRC_1Curr "Zone Fr 'IRC_1' pin electric current";
CM_ SG_ 498 FrPMMLimpHomeActReq "PMM Limp Home act request";
CM_ SG_ 498 FrPMMLVOutPErrLmp "PMM LV output error lamp request";
CM_ SG_ 498 FrPMMSysErrLmp "PMM system error lamp request";
CM_ SG_ 498 FrPwrStdbyA1Fault "Zone Fr 'Power_Standby_A1' pin fault state";
CM_ SG_ 498 FrEDU_INVERTERFault "Zone Fr 'INVERTER' pin fault state";
CM_ SG_ 498 FrBMS_CCU_CIRFault "Zone Fr 'BMS_CCU_CIR' pin fault state";
CM_ SG_ 498 FrPwrONA1Fault "Zone Fr 'Power_ON_A1' pin fault state";
CM_ SG_ 498 FrPwrStdbyA2PlusFault "Zone Fr 'Power_Standby_A2+' pin fault state";
CM_ SG_ 498 FrPwrStdbyA1PlusFault "Zone Fr 'Power_Standby_A1+' pin fault state";
CM_ SG_ 498 FrEDU_INVERTERCurr "Zone Fr 'INVERTER' pin electric current";
CM_ SG_ 498 FrBMS_CCU_CIRCurr "Zone Fr 'BMS_CCU_CIR' pin electric current";
CM_ SG_ 498 FrPwrStdbyA2PlusCurr "Zone Fr 'Power_Standby_A2+' pin electric current";
CM_ SG_ 498 ZoneFrMalfunLevel "Zone Fr VCU error level";
CM_ SG_ 498 ZFR_SYS_BMSCCURetryCnt_Sta "Zone FR BMS_CCU power output pin retry count";
CM_ SG_ 498 ZFR_SYS_MCURetryCnt_Sta "Zone FR MCU power output pin retry count";
CM_ SG_ 498 ZFR_SYS_BSWSleepReq_Sta "Zone FR sleep request from BSW";
CM_ SG_ 498 FrBMSCCUCErr "Zone Fr BMS CCU power pin current error state";
CM_ SG_ 498 FrEDUErr "Zone Fr EDU power pin current error state";
CM_ SG_ 498 FrStdA1PCErr "Zone Fr power standby A1 plus power pin current error state";
CM_ SG_ 498 FrStdA2PCErr "Zone Fr power standby A2 plus power pin current error state";
CM_ SG_ 498 FrStdA2PErr "Zone Fr power standby A2 plus power pin error state";
CM_ SG_ 498 FrPwrSta "FR PwrSta transmit";
CM_ SG_ 498 ZFR_VCU_HWReset_Sta "Zone Fr VCU hardware reset state";
CM_ SG_ 498 ZFR_VCU_PwrSupply_Sta "Zone Fr VCU power supply state";
CM_ SG_ 515 AirBagFailCmd "Airbag system lamp status";
CM_ SG_ 515 DriverSeatBeltCmd "Driver Seat Belt lamp status";
CM_ SG_ 515 PsngrSeatBeltCmd "Passenger Seat Belt lamp status";
CM_ SG_ 515 PABSwitchCmd "PAB Switch lamp status";
CM_ SG_ 515 RDriverSeatBeltCmd "Rear driver seat belt lamp status";
CM_ SG_ 515 RPsngrSeatBeltCmd "Rear passenger seat belt lamp status";
CM_ SG_ 515 RCenterSeatBeltCmd "Rear center seat belt lamp status";
CM_ SG_ 515 TLHPsngrSeatBeltCmd "Third LH seatbelt lamp status";
CM_ SG_ 515 TRHPsngrSeatBeltCmd "Third RH seatbelt lamp status";
CM_ SG_ 515 CrashOutputSts "Crash Output Status";
CM_ SG_ 515 LifeCount_ABM1 "RollingCounter of ABM";
CM_ SG_ 515 Checksum_ABM1 "Check sum of ABM";
CM_ SG_ 517 SRR1_Chksum "Checksum of SRR1";
CM_ SG_ 517 SRR_RCTA_WarnR "RCTA Warning Right";
CM_ SG_ 517 SRR_RCTA_WarnL "RCTA Warning Left";
CM_ SG_ 517 SRR_BSD_WarnR "BSD Warning Right";
CM_ SG_ 517 SRR_BSD_WarnL "BSD Warning Left";
CM_ SG_ 517 SRR_BSD_SoundR "BSD Sound Right";
CM_ SG_ 517 SRR_BSD_SoundL "BSD Sound Left";
CM_ SG_ 517 SRR_BSD_Mute "BSD Mute status";
CM_ SG_ 517 SRR_ODA_WarnR "ODA Warning Right";
CM_ SG_ 517 SRR_ODA_WarnL "ODA Warning Left";
CM_ SG_ 517 SRR_ODA_SoundR "ODA Sound Right";
CM_ SG_ 517 SRR_ODA_SoundL "ODA Sound Left";
CM_ SG_ 517 SRR_ODA_Mute "ODA Mute Status";
CM_ SG_ 517 SRR_ODA_Sta "Status of ODA";
CM_ SG_ 517 SRR_BSD_Sta "Status of BSD";
CM_ SG_ 517 SRR_RCTA_Sta "Status of RCTA";
CM_ SG_ 517 SRR_FltWrnReq "SRR Fault Warning Request";
CM_ SG_ 517 SRR1_LifeCount "Rolling Counter of SRR1";
CM_ SG_ 528 PAS_A_FCL "To show the level of distance detected from sensor FCL";
CM_ SG_ 528 PAS_Chime "The types of chime for PSS system";
CM_ SG_ 528 APS_Progress_PCT "information for show the APA operation percentage";
CM_ SG_ 528 APS_RQ_Display "Request to show the APA operation";
CM_ SG_ 528 PAS_D_RMR "To show the distance detected from sensor RMR";
CM_ SG_ 528 PAS_D_RML "To show the distance detected from sensor RML";
CM_ SG_ 528 PAS_D_RCR "To show the distance detected from sensor RCR";
CM_ SG_ 528 PAS_D_RCL "To show the distance detected from sensor RCL";
CM_ SG_ 528 APS_SW_Ver "APS Software Version Number";
CM_ SG_ 528 APS_HW_Ver "APS Hardware Version Number";
CM_ SG_ 528 APS_ExitCondition "APS Disable Cause";
CM_ SG_ 528 PAS_D_FMR "To show the distance detected from sensor FMR";
CM_ SG_ 528 PAS_D_FML "To show the distance detected from sensor FML";
CM_ SG_ 528 PAS_D_FCR "To show the distance detected from sensor FCR";
CM_ SG_ 528 PAS_D_FCL "To show the distance detected from sensor FCL";
CM_ SG_ 528 APS_D_RLR "To show the distance detected from sensor RLR";
CM_ SG_ 528 APS_D_RLL "To show the distance detected from sensor RLL";
CM_ SG_ 528 APS_D_FLR "To show the distance detected from sensor FLR";
CM_ SG_ 528 APS_D_FLL "To show the distance detected from sensor FLL";
CM_ SG_ 528 PAS_SNSR_Layout "To show the sensor layout";
CM_ SG_ 528 PAS_A_RMR "To show the level of distance detected from sensor RMR";
CM_ SG_ 528 PAS_A_RML "To show the level of distance detected from sensor RML";
CM_ SG_ 528 PAS_A_RCR "To show the level of distance detected from sensor RCR";
CM_ SG_ 528 PAS_A_RCL "To show the level of distance detected from sensor RCL";
CM_ SG_ 528 PAS_A_FMR "To show the level of distance detected from sensor FMR";
CM_ SG_ 528 PAS_A_FML "To show the level of distance detected from sensor FML";
CM_ SG_ 528 PAS_A_FCR "To show the level of distance detected from sensor FCR";
CM_ SG_ 528 PAS_Sta_F_Sys "PBS_SYS_FAIL";
CM_ SG_ 528 PAS_Mod_Operation "To show the operation mode of system";
CM_ SG_ 528 USS_Sta_RMR "USS RMR Fault status";
CM_ SG_ 528 USS_Sta_RML "USS RML Fault status";
CM_ SG_ 528 USS_Sta_RLR "USS RLR Fault status";
CM_ SG_ 528 USS_Sta_RLL "USS RLL Fault status";
CM_ SG_ 528 USS_Sta_RCR "USS RCR Fault status";
CM_ SG_ 528 USS_Sta_RCL "USS RCL Fault status";
CM_ SG_ 528 USS_Sta_FMR "USS FMR Fault status";
CM_ SG_ 528 USS_Sta_FML "USS FML Fault status";
CM_ SG_ 528 USS_Sta_FLR "USS FLR Fault status";
CM_ SG_ 528 USS_Sta_FLL "USS FLL Fault status";
CM_ SG_ 528 USS_Sta_FCR "USS FCR Fault status";
CM_ SG_ 528 USS_Sta_FCL "USS FCL Fault status";
CM_ SG_ 528 FDC_VCU_RegenLimInd_Sta "Regen Temporary Limit Indicator";
CM_ SG_ 528 FDC_VCU_SmartEco_Sta "smart ECO mode VCU state";
CM_ SG_ 528 FDC_VCU_SmartEcoSpdLim_Sta "Speed limit during smart ECO";
CM_ SG_ 534 DrDoorSW "Driver Side Door Switch";
CM_ SG_ 534 PsDoorSW "Passenger Side Door Switch";
CM_ SG_ 534 RLDoorSW "Rear Left Door Switch";
CM_ SG_ 534 RRDoorSW "Rear Right Door Switch";
CM_ SG_ 534 AllDoorSW "All Door Switch";
CM_ SG_ 534 DoorLockIND "Door Lock Indicator";
CM_ SG_ 534 HoodSW "Hood Switch";
CM_ SG_ 534 Tailgate_SW "Tailgate Switch";
CM_ SG_ 534 CTDCtrl "Door Lock Control";
CM_ SG_ 534 Fr_ChargingDoorCtrl "Front Charging Door Control";
CM_ SG_ 534 Rr_ChargingDoorCtrl "Rear Charging Door Control";
CM_ SG_ 534 CTDLockSW "Central Door Lock SW";
CM_ SG_ 534 CTDUnlockSW "Central Door Unlock SW";
CM_ SG_ 534 MirrorDefog "Mirror Defog";
CM_ SG_ 534 Rr_Defog "Rear Defog";
CM_ SG_ 534 TrunkRel "Trunk Release";
CM_ SG_ 534 TailgateHDSW "Tailgate Handle SW";
CM_ SG_ 534 MirrorCtrl "Mirror Control";
CM_ SG_ 534 Fr_Wiper_H "Front Wiper High";
CM_ SG_ 534 Fr_Wiper_L "Front Wiper LOW";
CM_ SG_ 534 Rr_Wiper "Rear Wiper";
CM_ SG_ 534 WiperFixMode "Wiper Fix Mode";
CM_ SG_ 534 WasherCtrl "WasherControl";
CM_ SG_ 534 L_Beam "Low Beam";
CM_ SG_ 534 H_Beam "High Beam";
CM_ SG_ 534 PosLamp "PositionLamp";
CM_ SG_ 534 LDRL "Left DRL";
CM_ SG_ 534 RDRL "Right DRL";
CM_ SG_ 534 ReverseLamp "ReverseLamp";
CM_ SG_ 534 BrakeLamp "BrakeLamp";
CM_ SG_ 534 LBSD "Left BSD";
CM_ SG_ 534 RBSD "Right BSD";
CM_ SG_ 534 Fr_FogLamp "Front Fog Lamp";
CM_ SG_ 534 Rr_FogLamp "Rear Fog Lamp";
CM_ SG_ 534 HazardSW "Hazard SW";
CM_ SG_ 534 LTurnLP "Left Turn Lamp";
CM_ SG_ 534 RTurnLP "Right Turn Lamp";
CM_ SG_ 534 AntitheftSta "Anti-theft Status";
CM_ SG_ 534 AntiTheftSeatFold "Anti-theft Seat Fold";
CM_ SG_ 534 CrashDetd "Crash Detected";
CM_ SG_ 534 L_APM_WdwEnable "Enable windows movement";
CM_ SG_ 534 Dimmer "Dimmer";
CM_ SG_ 534 LockSetting "BCM Unlock Single Door Setting";
CM_ SG_ 534 BCM_Buzzer_Req "BCM Buzzer Request";
CM_ SG_ 534 TailgateRemote "Remote Control PTG";
CM_ SG_ 534 RoomLampL "Room Lamp Low";
CM_ SG_ 534 RoomLampH "Room Lamp High";
CM_ SG_ 534 DimmerEN "Dimmer Enable";
CM_ SG_ 534 BCM_DoorLock_Sta "BCM Unlock Single Door Setting";
CM_ SG_ 534 HornCtrl "Horn Control";
CM_ SG_ 534 FollowMe "Follow Me Home Signal";
CM_ SG_ 534 APMDoorControlSta "APM Door Control Function Status
FDC BCM Tx";
CM_ SG_ 534 FDC_BCM_LockAlarm_Cmd "Lock alarm command";
CM_ SG_ 534 FDC_THCM_APTCWarning_Sta "APTC Fail Warning";

BA_DEF_ "NmType" STRING ;
BA_DEF_ "VersionYear" INT 2010 2999;
BA_DEF_ "ProtocolType" STRING ;
BA_DEF_ "NmMessageCount" INT 0 255;
BA_DEF_ "NmBaseAddress" HEX 1280 1407;
BA_DEF_ "DBName" STRING ;
BA_DEF_ "BusType" STRING ;
BA_DEF_ "Baudrate" INT 0 1000000;
BA_DEF_ "Datarate" INT 0 2000000;
BA_DEF_ BU_ "NodeLayerModules" STRING ;
BA_DEF_ BU_ "NmCAN" INT 1 2;
BA_DEF_ BU_ "ILUsed" ENUM "No","Yes";
BA_DEF_ BU_ "CANFD_CANFD_Gateway" ENUM "Yes","No";
BA_DEF_ BO_ "GenMsgSendType" ENUM "Cycle","NoMsgSendType","IfActive","Event","CA","CE";
BA_DEF_ BO_ "GenMsgNrOfRepetition" INT 0 0;
BA_DEF_ BO_ "GenMsgILSupport" ENUM "No","Yes";
BA_DEF_ BO_ "GenMsgDelayTime" INT 0 0;
BA_DEF_ BO_ "GenMsgCycleTimeFast" INT 0 0;
BA_DEF_ BO_ "GenMsgCycleTime" INT 0 0;
BA_DEF_ BO_ "DiagResponse" ENUM "No","Yes";
BA_DEF_ BO_ "DiagRequest" ENUM "No","Yes";
BA_DEF_ BO_ "NmMessage" ENUM "No","Yes";
BA_DEF_ BO_ "VFrameFormat" ENUM "StandardCAN","ExtendedCAN","reserved","reserved","reserved","reserved","reserved","reserved","reserved","reserved","reserved","reserved","reserved","reserved","StandardCAN_FD","ExtendedCAN_FD";
BA_DEF_ BO_ "GenMsgRequestable" INT 0 1;
BA_DEF_ BO_ "DataID_Hex" HEX 0 65535;
BA_DEF_ BO_ "DoIPLogicalAddress" STRING ;
BA_DEF_ BO_ "DataID" STRING ;
BA_DEF_ BO_ "CANFD_BRS" ENUM "0","1";
BA_DEF_ SG_ "GenSigInvalidValue" HEX 0 0;
BA_DEF_ SG_ "GenSigStartValue" HEX 0 0;
BA_DEF_ SG_ "GenSigInactiveValue" HEX 0 0;
BA_DEF_ SG_ "GenSigRoutingTimeoutValue_String" STRING ;
BA_DEF_ SG_ "GenSigRoutingTimeoutValue" HEX 0 0;
BA_DEF_ SG_ "GenSigSendType" ENUM "Cycle","OnWrite","OnWriteWithRepetition","OnChange","OnChangeWithRepetition","IfActive","IfActiveWithRepetition","NoSigSendType","vector_leerstring";
BA_DEF_ SG_ "SigType" ENUM "Default","Range","RangeSigned","ASCII","Discrete","Control","ReferencePGN","DTC","StringDelimiter","StringLength","StringLengthControl","MessageCounter","MessageChecksum";
BA_DEF_ SG_ "GenSigILSupport" ENUM "No","Yes";
BA_DEF_DEF_ "NmType" "AUTOSAR";
BA_DEF_DEF_ "VersionYear" 2023;
BA_DEF_DEF_ "ProtocolType" "CAN";
BA_DEF_DEF_ "NmMessageCount" 128;
BA_DEF_DEF_ "NmBaseAddress" 1280;
BA_DEF_DEF_ "DBName" "";
BA_DEF_DEF_ "BusType" "";
BA_DEF_DEF_ "Baudrate" 500000;
BA_DEF_DEF_ "Datarate" 2000000;
BA_DEF_DEF_ "NodeLayerModules" "CANoeILNLVector.dll";
BA_DEF_DEF_ "NmCAN" 2;
BA_DEF_DEF_ "ILUsed" "Yes";
BA_DEF_DEF_ "CANFD_CANFD_Gateway" "No";
BA_DEF_DEF_ "GenMsgSendType" "Cycle";
BA_DEF_DEF_ "GenMsgNrOfRepetition" 0;
BA_DEF_DEF_ "GenMsgILSupport" "Yes";
BA_DEF_DEF_ "GenMsgDelayTime" 0;
BA_DEF_DEF_ "GenMsgCycleTimeFast" 0;
BA_DEF_DEF_ "GenMsgCycleTime" 100;
BA_DEF_DEF_ "DiagResponse" "No";
BA_DEF_DEF_ "DiagRequest" "No";
BA_DEF_DEF_ "NmMessage" "No";
BA_DEF_DEF_ "VFrameFormat" "StandardCAN";
BA_DEF_DEF_ "GenMsgRequestable" 1;
BA_DEF_DEF_ "DataID_Hex" 0;
BA_DEF_DEF_ "DoIPLogicalAddress" "";
BA_DEF_DEF_ "DataID" "";
BA_DEF_DEF_ "CANFD_BRS" "1";
BA_DEF_DEF_ "GenSigInvalidValue" 0;
BA_DEF_DEF_ "GenSigStartValue" 0;
BA_DEF_DEF_ "GenSigInactiveValue" 0;
BA_DEF_DEF_ "GenSigRoutingTimeoutValue_String" "";
BA_DEF_DEF_ "GenSigRoutingTimeoutValue" 0;
BA_DEF_DEF_ "GenSigSendType" "Cycle";
BA_DEF_DEF_ "SigType" "Default";
BA_DEF_DEF_ "GenSigILSupport" "Yes";
BA_ "BusType" "CAN FD";
BA_ "ProtocolType" "CAN FD";
BA_ "DBName" "CAN2";
BA_ "CANFD_CANFD_Gateway" BU_ FUSION 0;
BA_ "GenMsgNrOfRepetition" BO_ 278 1;
BA_ "DataID_Hex" BO_ 278 27733;
BA_ "DataID" BO_ 278 "0x6C55";
BA_ "GenMsgCycleTimeFast" BO_ 278 10;
BA_ "GenMsgSendType" BO_ 278 5;
BA_ "VFrameFormat" BO_ 278 14;
BA_ "GenMsgCycleTime" BO_ 338 10;
BA_ "VFrameFormat" BO_ 338 14;
BA_ "GenMsgCycleTime" BO_ 360 10;
BA_ "VFrameFormat" BO_ 360 14;
BA_ "GenMsgCycleTime" BO_ 369 10;
BA_ "VFrameFormat" BO_ 369 14;
BA_ "GenMsgCycleTime" BO_ 377 10;
BA_ "VFrameFormat" BO_ 377 14;
BA_ "GenMsgNrOfRepetition" BO_ 378 1;
BA_ "GenMsgCycleTimeFast" BO_ 378 10;
BA_ "GenMsgSendType" BO_ 378 5;
BA_ "VFrameFormat" BO_ 378 14;
BA_ "GenMsgCycleTime" BO_ 380 10;
BA_ "VFrameFormat" BO_ 380 14;
BA_ "GenMsgNrOfRepetition" BO_ 383 1;
BA_ "GenMsgSendType" BO_ 383 5;
BA_ "VFrameFormat" BO_ 383 14;
BA_ "VFrameFormat" BO_ 386 14;
BA_ "GenMsgNrOfRepetition" BO_ 389 1;
BA_ "GenMsgCycleTime" BO_ 389 10;
BA_ "GenMsgCycleTimeFast" BO_ 389 10;
BA_ "VFrameFormat" BO_ 389 14;
BA_ "GenMsgNrOfRepetition" BO_ 395 1;
BA_ "GenMsgCycleTime" BO_ 395 10;
BA_ "GenMsgCycleTimeFast" BO_ 395 10;
BA_ "GenMsgSendType" BO_ 395 5;
BA_ "VFrameFormat" BO_ 395 14;
BA_ "GenMsgCycleTime" BO_ 402 10;
BA_ "VFrameFormat" BO_ 402 14;
BA_ "GenMsgCycleTime" BO_ 406 10;
BA_ "VFrameFormat" BO_ 406 14;
BA_ "GenMsgCycleTime" BO_ 408 200;
BA_ "VFrameFormat" BO_ 408 14;
BA_ "GenMsgCycleTime" BO_ 410 10;
BA_ "VFrameFormat" BO_ 410 14;
BA_ "GenMsgCycleTime" BO_ 412 200;
BA_ "VFrameFormat" BO_ 412 14;
BA_ "GenMsgCycleTime" BO_ 419 10;
BA_ "VFrameFormat" BO_ 419 14;
BA_ "GenMsgCycleTime" BO_ 421 10;
BA_ "VFrameFormat" BO_ 421 14;
BA_ "GenMsgCycleTime" BO_ 425 10;
BA_ "VFrameFormat" BO_ 425 14;
BA_ "GenMsgCycleTime" BO_ 427 40;
BA_ "VFrameFormat" BO_ 427 14;
BA_ "GenMsgNrOfRepetition" BO_ 470 1;
BA_ "GenMsgCycleTimeFast" BO_ 470 10;
BA_ "GenMsgSendType" BO_ 470 5;
BA_ "VFrameFormat" BO_ 470 14;
BA_ "GenMsgNrOfRepetition" BO_ 497 1;
BA_ "GenMsgCycleTime" BO_ 497 20;
BA_ "GenMsgCycleTimeFast" BO_ 497 5;
BA_ "GenMsgSendType" BO_ 497 5;
BA_ "VFrameFormat" BO_ 497 14;
BA_ "GenMsgNrOfRepetition" BO_ 498 1;
BA_ "GenMsgCycleTime" BO_ 498 20;
BA_ "GenMsgCycleTimeFast" BO_ 498 5;
BA_ "GenMsgSendType" BO_ 498 5;
BA_ "VFrameFormat" BO_ 498 14;
BA_ "GenMsgNrOfRepetition" BO_ 515 1;
BA_ "GenMsgCycleTime" BO_ 515 500;
BA_ "GenMsgCycleTimeFast" BO_ 515 50;
BA_ "GenMsgSendType" BO_ 515 5;
BA_ "VFrameFormat" BO_ 515 14;
BA_ "VFrameFormat" BO_ 517 14;
BA_ "GenMsgCycleTime" BO_ 528 20;
BA_ "VFrameFormat" BO_ 528 14;
BA_ "GenMsgNrOfRepetition" BO_ 534 1;
BA_ "GenMsgCycleTime" BO_ 534 200;
BA_ "GenMsgCycleTimeFast" BO_ 534 60;
BA_ "GenMsgSendType" BO_ 534 5;
BA_ "VFrameFormat" BO_ 534 14;
BA_ "GenSigSendType" SG_ 278 XWDMode 3;
BA_ "GenSigSendType" SG_ 278 PwrSta 3;
BA_ "GenSigSendType" SG_ 278 DCDCVoltSetpoint 3;
BA_ "GenSigSendType" SG_ 278 DCDCEnaReq 3;
BA_ "GenSigSendType" SG_ 278 Fr_MCUEnaReq 3;
BA_ "GenSigSendType" SG_ 278 Rr_MCUEnaReq 3;
BA_ "GenSigSendType" SG_ 278 HVBatCnctReq 3;
BA_ "GenSigSendType" SG_ 278 ActiveDischReq 3;
BA_ "GenSigSendType" SG_ 278 PrkReq 3;
BA_ "GenSigSendType" SG_ 278 Fr_ActvDmpDisabReq 3;
BA_ "GenSigSendType" SG_ 278 Rr_ActvDmpDisabReq 3;
BA_ "GenSigSendType" SG_ 278 HVSysReadyToCharge 3;
BA_ "GenSigSendType" SG_ 278 ShiftGearPosn 3;
BA_ "GenSigInvalidValue" SG_ 278 LVChrgFuncStaChk 3;
BA_ "GenSigInvalidValue" SG_ 278 CC_Crl_Sta 6;
BA_ "GenSigSendType" SG_ 278 CC_Crl_Sta 3;
BA_ "GenSigInvalidValue" SG_ 278 MSA_Crl_Sta 6;
BA_ "GenSigSendType" SG_ 278 MSA_Crl_Sta 3;
BA_ "GenSigInvalidValue" SG_ 278 DemoModeStaChk 3;
BA_ "GenSigInvalidValue" SG_ 278 CoastDwModeStaChk 3;
BA_ "GenSigInvalidValue" SG_ 278 DynoModeStaChk 3;
BA_ "GenSigSendType" SG_ 278 FalseNPrevent_Sta 3;
BA_ "GenSigSendType" SG_ 278 DisengageP_Fail 3;
BA_ "GenSigSendType" SG_ 278 EngageP_Fail 3;
BA_ "GenSigSendType" SG_ 278 CreepSW_Sta 3;
BA_ "GenSigSendType" SG_ 278 FDC_VCU_PwrSaveReq_Cmd 3;
BA_ "GenSigInvalidValue" SG_ 338 RearAxlTrqReq_Drv 65535;
BA_ "GenSigStartValue" SG_ 338 RearAxlTrqReq_Drv 10600;
BA_ "GenSigInvalidValue" SG_ 338 FrntAxlTrqReq_Drv 65535;
BA_ "GenSigStartValue" SG_ 338 FrntAxlTrqReq_Drv 10600;
BA_ "GenSigInvalidValue" SG_ 338 VehSpeed 4095;
BA_ "GenSigRoutingTimeoutValue" SG_ 338 VehSpeed 4095;
BA_ "GenSigStartValue" SG_ 369 HVBPwrAvailDchrg30 1500;
BA_ "GenSigStartValue" SG_ 369 HVBPwrAvailChrg 1500;
BA_ "GenSigStartValue" SG_ 369 HVBPwrAvailDchrg 1500;
BA_ "GenSigStartValue" SG_ 369 HVBPwrAvailChrg60 1500;
BA_ "GenSigStartValue" SG_ 369 HVBPwrAvailDchrg60 1500;
BA_ "GenSigInvalidValue" SG_ 369 HVBattCurr 32767;
BA_ "GenSigStartValue" SG_ 369 HVBattCurr 10000;
BA_ "GenSigInvalidValue" SG_ 377 ACC_ComfortBandLower 511;
BA_ "GenSigInvalidValue" SG_ 377 ACC_JerkLowerLimit 127;
BA_ "GenSigInvalidValue" SG_ 377 ACC_ComfortBandUpper 511;
BA_ "GenSigInvalidValue" SG_ 377 ACC_JerkUpperLimit 127;
BA_ "GenSigSendType" SG_ 378 BMS_Warn_1 3;
BA_ "GenSigSendType" SG_ 378 BMS_Warn_2 3;
BA_ "GenSigSendType" SG_ 378 BMS_Warn_3 3;
BA_ "GenSigSendType" SG_ 378 BMS_Warn_4 3;
BA_ "GenSigSendType" SG_ 378 BMS_Warn_5 3;
BA_ "GenSigSendType" SG_ 378 BMS_Warn_6 3;
BA_ "GenSigSendType" SG_ 378 BMS_Warn_7 3;
BA_ "GenSigSendType" SG_ 378 BMS_Warn_8 3;
BA_ "GenSigSendType" SG_ 378 HVBOvrTempWarn 3;
BA_ "GenSigSendType" SG_ 378 HVBUndrTempWarn 3;
BA_ "GenSigSendType" SG_ 378 HVBOvrVoltErr 3;
BA_ "GenSigSendType" SG_ 378 HVBUndrVoltErr 3;
BA_ "GenSigSendType" SG_ 378 HVBShrtChrgCurrErr 3;
BA_ "GenSigSendType" SG_ 378 HVBShrtDischrgCurrErr 3;
BA_ "GenSigSendType" SG_ 378 HVBOvrChrgCurrErr 3;
BA_ "GenSigSendType" SG_ 378 HVBOvrDchrgCurErr 3;
BA_ "GenSigSendType" SG_ 378 HVBOvrTempErr 3;
BA_ "GenSigSendType" SG_ 378 HVBUndrTempErr 3;
BA_ "GenSigSendType" SG_ 378 HVBOvrSOCErr 3;
BA_ "GenSigSendType" SG_ 378 HVBUndrSOCErr 3;
BA_ "GenSigSendType" SG_ 378 HVBSOCJumpError 3;
BA_ "GenSigSendType" SG_ 378 HVBHVILErr 3;
BA_ "GenSigSendType" SG_ 378 DCChrgSysShockErr 3;
BA_ "GenSigSendType" SG_ 378 BMS_READY 3;
BA_ "GenSigSendType" SG_ 378 HVBContactorSta 3;
BA_ "GenSigSendType" SG_ 378 HVBPrechrgSta 3;
BA_ "GenSigSendType" SG_ 378 HVBTempDiffErr 3;
BA_ "GenSigSendType" SG_ 378 HVILSta 3;
BA_ "GenSigSendType" SG_ 378 HVBattReady4Pre 3;
BA_ "GenSigSendType" SG_ 378 ChrgPlugSta 3;
BA_ "GenSigSendType" SG_ 378 ExtChrgSta 3;
BA_ "GenSigSendType" SG_ 378 HVBPreheatPrecoolSta 3;
BA_ "GenSigSendType" SG_ 378 IsoDetSta 3;
BA_ "GenSigSendType" SG_ 378 SystemUncomErr 3;
BA_ "GenSigSendType" SG_ 378 CellUnconsistErr 3;
BA_ "GenSigSendType" SG_ 378 HVBCellOvrVoltWarn 3;
BA_ "GenSigSendType" SG_ 378 HVBCellUdrVoltWarn 3;
BA_ "GenSigSendType" SG_ 378 HVBCellOvrVoltErr 3;
BA_ "GenSigSendType" SG_ 378 HVBCellUndrVoltErr 3;
BA_ "GenSigSendType" SG_ 378 HVBCellUnbalanErr 3;
BA_ "GenSigSendType" SG_ 378 ChrgInLockReq 3;
BA_ "GenSigSendType" SG_ 378 DisChrgPlugErr 3;
BA_ "GenSigSendType" SG_ 378 HVBChrgErr 3;
BA_ "GenSigSendType" SG_ 378 V2LSta 3;
BA_ "GenSigInvalidValue" SG_ 380 ACC_ObjRelSpd 2047;
BA_ "GenSigInvalidValue" SG_ 380 ACC_ObjDist 2047;
BA_ "GenSigStartValue" SG_ 380 ACC_ObjDist 2046;
BA_ "GenSigSendType" SG_ 383 CCMSA_SpdWar 3;
BA_ "GenSigStartValue" SG_ 386 Rr_Coolanttemp 40;
BA_ "GenSigStartValue" SG_ 386 sigClntTHvBattOut 120;
BA_ "GenSigStartValue" SG_ 386 sigCbnSolarLeft 253;
BA_ "GenSigStartValue" SG_ 386 sigCbnSolarRight 253;
BA_ "GenSigInvalidValue" SG_ 386 sigAmbAirT 255;
BA_ "GenSigInvalidValue" SG_ 386 sigAirIntenZon1St 15;
BA_ "GenSigStartValue" SG_ 386 Fr_Coolanttemp 40;
BA_ "GenSigStartValue" SG_ 389 OBCDCCurrInf 255;
BA_ "GenSigSendType" SG_ 395 OBCV2LINVOTP 3;
BA_ "GenSigSendType" SG_ 395 OBCV2LInsuFault 3;
BA_ "GenSigSendType" SG_ 395 OBCV2LVoutOCP 3;
BA_ "GenSigSendType" SG_ 395 OBCV2LVoutOVP 3;
BA_ "GenSigSendType" SG_ 395 OBCV2LVoutUVP 3;
BA_ "GenSigInvalidValue" SG_ 402 Rr_EDUTqReqFbk 4095;
BA_ "GenSigStartValue" SG_ 402 Rr_EDUTqReqFbk 1022;
BA_ "GenSigStartValue" SG_ 402 Rr_EDURealTMTq 1022;
BA_ "GenSigStartValue" SG_ 402 Rr_TMSpd 17000;
BA_ "GenSigInvalidValue" SG_ 402 Rr_MCUDCBusVolt 65535;
BA_ "GenSigInvalidValue" SG_ 402 Rr_MCUDCBusCurr 32767;
BA_ "GenSigStartValue" SG_ 402 Rr_MCUDCBusCurr 15000;
BA_ "GenSigInvalidValue" SG_ 402 Rr_MCUTemp 511;
BA_ "GenSigInvalidValue" SG_ 402 Rr_TMTemp 511;
BA_ "GenSigInvalidValue" SG_ 402 Rr_TMid 32767;
BA_ "GenSigStartValue" SG_ 402 Rr_TMid 15000;
BA_ "GenSigInvalidValue" SG_ 402 Rr_TMiq 32767;
BA_ "GenSigStartValue" SG_ 402 Rr_TMiq 15000;
BA_ "GenSigInvalidValue" SG_ 402 Rr_MotorAvailTq 4095;
BA_ "GenSigInvalidValue" SG_ 402 Rr_RegenAvailTq 4095;
BA_ "GenSigInvalidValue" SG_ 402 Rr_MCUBAT 255;
BA_ "GenSigStartValue" SG_ 402 MCUWarn_R 7;
BA_ "GenSigInvalidValue" SG_ 406 Fr_EDUTqReqFbk 4095;
BA_ "GenSigStartValue" SG_ 406 Fr_EDUTqReqFbk 1022;
BA_ "GenSigStartValue" SG_ 406 Fr_TMSpd 17000;
BA_ "GenSigInvalidValue" SG_ 406 Fr_MCUDCBusVolt 65535;
BA_ "GenSigInvalidValue" SG_ 406 Fr_MCUDCBusCurr 32767;
BA_ "GenSigInvalidValue" SG_ 406 Fr_MCUTemp 511;
BA_ "GenSigInvalidValue" SG_ 406 Fr_TMTemp 511;
BA_ "GenSigInvalidValue" SG_ 406 Fr_TMid 32767;
BA_ "GenSigInvalidValue" SG_ 406 Fr_TMiq 32767;
BA_ "GenSigInvalidValue" SG_ 406 Fr_MotorAvailTq 4095;
BA_ "GenSigInvalidValue" SG_ 406 Fr_RegenAvailTq 4095;
BA_ "GenSigInvalidValue" SG_ 406 Fr_MCUBAT 255;
BA_ "GenSigStartValue" SG_ 406 MCUWarn_F 7;
BA_ "GenSigInvalidValue" SG_ 408 Fr_LLCTemp 511;
BA_ "GenSigInvalidValue" SG_ 408 Fr_LLCflowReq 63;
BA_ "GenSigInvalidValue" SG_ 408 Fr_EOP_SpdSet 4095;
BA_ "GenSigInvalidValue" SG_ 408 Fr_CoolanttempReq 511;
BA_ "GenSigStartValue" SG_ 408 Fr_CoolanttempReq 40;
BA_ "GenSigInvalidValue" SG_ 410 SAS_Angle 65535;
BA_ "GenSigStartValue" SG_ 410 SAS_Angle 9000;
BA_ "GenSigInvalidValue" SG_ 412 Rr_LLCTemp 511;
BA_ "GenSigStartValue" SG_ 412 Rr_LLCTemp 40;
BA_ "GenSigInvalidValue" SG_ 412 Rr_LLCflowReq 63;
BA_ "GenSigInvalidValue" SG_ 412 Rr_EOP_SpdSet 4095;
BA_ "GenSigInvalidValue" SG_ 412 Rr_CoolanttempReq 511;
BA_ "GenSigStartValue" SG_ 412 Rr_CoolanttempReq 40;
BA_ "GenSigStartValue" SG_ 419 GRADE 127;
BA_ "GenSigInvalidValue" SG_ 419 SystemVoltage 255;
BA_ "GenSigInvalidValue" SG_ 421 YawRate 2047;
BA_ "GenSigStartValue" SG_ 421 YawRate 1000;
BA_ "GenSigInvalidValue" SG_ 421 LatAccel 255;
BA_ "GenSigStartValue" SG_ 421 LatAccel 127;
BA_ "GenSigInvalidValue" SG_ 421 LongAccel 255;
BA_ "GenSigStartValue" SG_ 421 LongAccel 127;
BA_ "GenSigInvalidValue" SG_ 421 MCPressure 4095;
BA_ "GenSigStartValue" SG_ 421 MCPressure 97;
BA_ "GenSigInvalidValue" SG_ 421 YawRate_V 1;
BA_ "GenSigInvalidValue" SG_ 421 LatAccel_V 1;
BA_ "GenSigInvalidValue" SG_ 421 LongAccel_V 1;
BA_ "GenSigInvalidValue" SG_ 421 MCPressure_V 1;
BA_ "GenSigInvalidValue" SG_ 421 BrkSw_V 1;
BA_ "GenSigInvalidValue" SG_ 425 Meter_Ind_VehSpeed 4095;
BA_ "GenSigInvalidValue" SG_ 427 EPBStaL 7;
BA_ "GenSigInvalidValue" SG_ 427 EPBStaR 7;
BA_ "GenSigSendType" SG_ 470 OBCFaultSta 3;
BA_ "GenSigSendType" SG_ 470 DCDCFaultSta 3;
BA_ "GenSigSendType" SG_ 470 OBCReady4Pre 3;
BA_ "GenSigSendType" SG_ 470 DCDCReady4Pre 3;
BA_ "GenSigStartValue" SG_ 470 OBCTemp 160;
BA_ "GenSigStartValue" SG_ 470 DCDCTemp 64;
BA_ "GenSigSendType" SG_ 470 DCDCTemp 3;
BA_ "GenSigStartValue" SG_ 470 OBCDCP 350;
BA_ "GenSigSendType" SG_ 470 DCDCEnaSta 3;
BA_ "GenSigSendType" SG_ 470 OBCEnaSta 3;
BA_ "GenSigStartValue" SG_ 470 OBCACCurrInf 40;
BA_ "GenSigSendType" SG_ 470 OBC_AC_Cur_Lim 3;
BA_ "GenSigSendType" SG_ 470 OBCV2LSta 3;
BA_ "GenSigSendType" SG_ 470 ReqOBCV2LEna 3;
BA_ "GenSigSendType" SG_ 497 DrPMMLimpHomeActReq 3;
BA_ "GenSigSendType" SG_ 497 DrPMMLVOutPErrLmp 3;
BA_ "GenSigSendType" SG_ 497 DrPMMSysErrLmp 3;
BA_ "GenSigSendType" SG_ 497 ZDR_SYS_APMRetryCnt_Sta 3;
BA_ "GenSigSendType" SG_ 497 ZDR_SYS_CSWRetryCnt_Sta 3;
BA_ "GenSigSendType" SG_ 497 ZDR_SYS_BSWSleepReq_Sta 3;
BA_ "GenSigSendType" SG_ 497 DrAPWLINErr 3;
BA_ "GenSigSendType" SG_ 497 DrAPWStaErr 3;
BA_ "GenSigSendType" SG_ 497 DrONA1ErrSta 3;
BA_ "GenSigSendType" SG_ 497 DrPwrWinErrSta 3;
BA_ "GenSigSendType" SG_ 497 DrStdAErrSta 3;
BA_ "GenSigSendType" SG_ 497 DrInfoErrSta 3;
BA_ "GenSigSendType" SG_ 497 ZoneDrMalfunLevel 3;
BA_ "GenSigSendType" SG_ 497 ZDR_VCU_HWReset_Sta 3;
BA_ "GenSigSendType" SG_ 497 ZDR_VCU_PwrSupply_Sta 3;
BA_ "GenSigSendType" SG_ 498 FrPMMLimpHomeActReq 3;
BA_ "GenSigSendType" SG_ 498 FrPMMLVOutPErrLmp 3;
BA_ "GenSigSendType" SG_ 498 FrPMMSysErrLmp 3;
BA_ "GenSigSendType" SG_ 498 ZoneFrMalfunLevel 3;
BA_ "GenSigSendType" SG_ 498 ZFR_SYS_BMSCCURetryCnt_Sta 3;
BA_ "GenSigSendType" SG_ 498 ZFR_SYS_MCURetryCnt_Sta 3;
BA_ "GenSigSendType" SG_ 498 ZFR_SYS_BSWSleepReq_Sta 3;
BA_ "GenSigSendType" SG_ 498 FrBMSCCUCErr 3;
BA_ "GenSigSendType" SG_ 498 FrEDUErr 3;
BA_ "GenSigSendType" SG_ 498 FrStdA1PCErr 3;
BA_ "GenSigSendType" SG_ 498 FrStdA2PCErr 3;
BA_ "GenSigSendType" SG_ 498 FrStdA2PErr 3;
BA_ "GenSigSendType" SG_ 498 FrPwrSta 3;
BA_ "GenSigSendType" SG_ 498 ZFR_VCU_HWReset_Sta 3;
BA_ "GenSigSendType" SG_ 498 ZFR_VCU_PwrSupply_Sta 3;
BA_ "GenSigSendType" SG_ 515 AirBagFailCmd 3;
BA_ "GenSigSendType" SG_ 515 DriverSeatBeltCmd 3;
BA_ "GenSigSendType" SG_ 515 PsngrSeatBeltCmd 3;
BA_ "GenSigSendType" SG_ 515 PABSwitchCmd 3;
BA_ "GenSigSendType" SG_ 515 RDriverSeatBeltCmd 3;
BA_ "GenSigSendType" SG_ 515 RPsngrSeatBeltCmd 3;
BA_ "GenSigSendType" SG_ 515 RCenterSeatBeltCmd 3;
BA_ "GenSigSendType" SG_ 515 TLHPsngrSeatBeltCmd 3;
BA_ "GenSigSendType" SG_ 515 TRHPsngrSeatBeltCmd 3;
BA_ "GenSigSendType" SG_ 515 CrashOutputSts 3;
BA_ "GenSigSendType" SG_ 534 DrDoorSW 3;
BA_ "GenSigSendType" SG_ 534 PsDoorSW 3;
BA_ "GenSigSendType" SG_ 534 RLDoorSW 3;
BA_ "GenSigSendType" SG_ 534 RRDoorSW 3;
BA_ "GenSigSendType" SG_ 534 AllDoorSW 3;
BA_ "GenSigSendType" SG_ 534 DoorLockIND 3;
BA_ "GenSigSendType" SG_ 534 HoodSW 3;
BA_ "GenSigSendType" SG_ 534 Tailgate_SW 3;
BA_ "GenSigSendType" SG_ 534 CTDCtrl 3;
BA_ "GenSigSendType" SG_ 534 Fr_ChargingDoorCtrl 3;
BA_ "GenSigSendType" SG_ 534 Rr_ChargingDoorCtrl 3;
BA_ "GenSigSendType" SG_ 534 CTDLockSW 3;
BA_ "GenSigSendType" SG_ 534 CTDUnlockSW 3;
BA_ "GenSigSendType" SG_ 534 MirrorDefog 3;
BA_ "GenSigSendType" SG_ 534 Rr_Defog 3;
BA_ "GenSigSendType" SG_ 534 TrunkRel 3;
BA_ "GenSigSendType" SG_ 534 TailgateHDSW 3;
BA_ "GenSigSendType" SG_ 534 MirrorCtrl 3;
BA_ "GenSigSendType" SG_ 534 Fr_Wiper_H 3;
BA_ "GenSigSendType" SG_ 534 Fr_Wiper_L 3;
BA_ "GenSigSendType" SG_ 534 Rr_Wiper 3;
BA_ "GenSigSendType" SG_ 534 WiperFixMode 3;
BA_ "GenSigSendType" SG_ 534 WasherCtrl 3;
BA_ "GenSigSendType" SG_ 534 L_Beam 3;
BA_ "GenSigSendType" SG_ 534 H_Beam 3;
BA_ "GenSigSendType" SG_ 534 PosLamp 3;
BA_ "GenSigSendType" SG_ 534 LDRL 3;
BA_ "GenSigSendType" SG_ 534 RDRL 3;
BA_ "GenSigSendType" SG_ 534 ReverseLamp 3;
BA_ "GenSigSendType" SG_ 534 BrakeLamp 3;
BA_ "GenSigSendType" SG_ 534 LBSD 3;
BA_ "GenSigSendType" SG_ 534 RBSD 3;
BA_ "GenSigSendType" SG_ 534 Fr_FogLamp 3;
BA_ "GenSigSendType" SG_ 534 Rr_FogLamp 3;
BA_ "GenSigSendType" SG_ 534 HazardSW 3;
BA_ "GenSigSendType" SG_ 534 LTurnLP 3;
BA_ "GenSigSendType" SG_ 534 RTurnLP 3;
BA_ "GenSigSendType" SG_ 534 AntitheftSta 3;
BA_ "GenSigSendType" SG_ 534 AntiTheftSeatFold 3;
BA_ "GenSigSendType" SG_ 534 CrashDetd 3;
BA_ "GenSigSendType" SG_ 534 L_APM_WdwEnable 3;
BA_ "GenSigInvalidValue" SG_ 534 Dimmer 127;
BA_ "GenSigSendType" SG_ 534 Dimmer 3;
BA_ "GenSigSendType" SG_ 534 LockSetting 3;
BA_ "GenSigSendType" SG_ 534 BCM_Buzzer_Req 3;
BA_ "GenSigSendType" SG_ 534 TailgateRemote 3;
BA_ "GenSigSendType" SG_ 534 RoomLampL 3;
BA_ "GenSigSendType" SG_ 534 RoomLampH 3;
BA_ "GenSigSendType" SG_ 534 DimmerEN 3;
BA_ "GenSigSendType" SG_ 534 BCM_DoorLock_Sta 3;
BA_ "GenSigSendType" SG_ 534 HornCtrl 3;
BA_ "GenSigSendType" SG_ 534 APMDoorControlSta 3;
BA_ "GenSigSendType" SG_ 534 FDC_BCM_LockAlarm_Cmd 3;
BA_ "GenSigRoutingTimeoutValue_String" SG_ 534 FDC_THCM_APTCWarning_Sta "0x0";
BA_ "GenSigSendType" SG_ 534 FDC_THCM_APTCWarning_Sta 3;
VAL_ 278 XWDMode 2 "AWD" 1 "FWD" 0 "RWD";
VAL_ 278 PwrSta 5 "READY" 4 "ON" 3 "STANDBY" 2 "OFF-After-Run" 1 "OFF-Charging" 0 "OFF";
VAL_ 278 DCDCEnaReq 1 "Enable Request" 0 "Disable";
VAL_ 278 Fr_MCUEnaReq 1 "Enable Request" 0 "Disable";
VAL_ 278 Rr_MCUEnaReq 1 "Enable Request" 0 "Disable";
VAL_ 278 HVBatCnctReq 1 "Connect" 0 "Disconnect";
VAL_ 278 ActiveDischReq 1 "Request Active Discharge" 0 "No Request";
VAL_ 278 PrkReq 1 "Parking Requested" 0 "Parking Released";
VAL_ 278 Fr_ActvDmpDisabReq 1 "Disable Request" 0 "Enable Request";
VAL_ 278 Rr_ActvDmpDisabReq 1 "Disable Request" 0 "Enable Request";
VAL_ 278 HVSysReadyToCharge 3 "Disable" 2 "Fault" 1 "Allow charge" 0 "Allow discharge";
VAL_ 278 ShiftGearPosn 7 "Reverse" 6 "Failure" 5 "Drive" 4 "Neutral" 3 "Not used" 2 "Not used" 1 "Not used" 0 "Park";
VAL_ 278 LVChrgFuncStaChk 2 "Invalid" 1 "On" 0 "Off";
VAL_ 278 CC_Crl_Sta 7 "Pedal Override" 6 "Invalid" 5 "Error" 4 "Over Speed" 3 "Under Speed" 2 "Active" 1 "Standby" 0 "Off";
VAL_ 278 MSA_Crl_Sta 7 "Pedal Override" 6 "Invalid" 5 "Error" 4 "Over Speed" 3 "Under Speed" 2 "Active" 1 "Standby" 0 "Off";
VAL_ 278 DemoModeStaChk 2 "Invalid" 1 "Ready" 0 "Not ready";
VAL_ 278 CoastDwModeStaChk 2 "Invalid" 1 "Ready" 0 "Not ready";
VAL_ 278 DynoModeStaChk 2 "Invalid" 1 "Ready" 0 "Not ready";
VAL_ 278 Dr_SeatSta 2 "Invalid" 1 "Seat occupied" 0 "Seat empty";
VAL_ 278 FalseNPrevent_Sta 1 "Enable" 0 "Disable";
VAL_ 278 DisengageP_Fail 1 "Fail" 0 "Off";
VAL_ 278 EngageP_Fail 1 "Fail" 0 "Off";
VAL_ 278 CreepSW_Sta 1 "On" 0 "Off";
VAL_ 278 VCU_OPDHold 1 "On" 0 "Off";
VAL_ 278 FDC_VCU_PwrSaveReq_Cmd 1 "Request power save" 0 "No request";
VAL_ 338 Fr_PTCS_Active 1 "Active" 0 "Inactive";
VAL_ 338 Rr_PTCS_Active 1 "Active" 0 "Inactive";
VAL_ 360 LowBrakeFluid_Sta 1 "Low" 0 "Normal";
VAL_ 360 eBST_AmberWnlmpSta 1 "On" 0 "Off";
VAL_ 360 eBST_RedWnlmpSta 1 "On" 0 "Off";
VAL_ 360 eBST_BeepReq 1 "Request" 0 "No Request";
VAL_ 377 ADAS_AEBReq 3 "Request Level III" 2 "Request Level II" 1 "Request Level I" 0 "No Request";
VAL_ 377 ADAS_FaultSta 1 "Fault" 0 "Normal";
VAL_ 377 AEB_VehHoldReq 1 "Request" 0 "No Request";
VAL_ 377 ADAS_DBSReq 3 "DBS Level III" 2 "DBS Level II" 1 "DBS Level I" 0 "No Request";
VAL_ 377 ACC_VehHoldReq 1 "Request" 0 "No Request";
VAL_ 378 BMS_Warn_1 1 "fault" 0 "No fault";
VAL_ 378 BMS_Warn_2 1 "fault" 0 "No fault";
VAL_ 378 BMS_Warn_3 1 "fault" 0 "No fault";
VAL_ 378 BMS_Warn_4 1 "fault" 0 "No fault";
VAL_ 378 BMS_Warn_5 1 "fault" 0 "No fault";
VAL_ 378 BMS_Warn_6 1 "fault" 0 "No fault";
VAL_ 378 BMS_Warn_7 1 "fault" 0 "No fault";
VAL_ 378 BMS_Warn_8 1 "fault" 0 "No fault";
VAL_ 378 HVBOvrTempWarn 2 "Warn2" 1 "Warn1" 0 "No fault";
VAL_ 378 HVBUndrTempWarn 2 "Warn2" 1 "Warn1" 0 "No fault";
VAL_ 378 HVBOvrVoltErr 1 "fault" 0 "No fault";
VAL_ 378 HVBUndrVoltErr 1 "fault" 0 "No fault";
VAL_ 378 HVBShrtChrgCurrErr 1 "fault" 0 "No fault";
VAL_ 378 HVBShrtDischrgCurrErr 1 "fault" 0 "No fault";
VAL_ 378 HVBOvrChrgCurrErr 1 "fault" 0 "No fault";
VAL_ 378 HVBOvrDchrgCurErr 1 "fault" 0 "No fault";
VAL_ 378 HVBOvrTempErr 1 "fault" 0 "No fault";
VAL_ 378 HVBUndrTempErr 1 "fault" 0 "No fault";
VAL_ 378 HVBOvrSOCErr 1 "fault" 0 "No fault";
VAL_ 378 HVBUndrSOCErr 1 "fault" 0 "No fault";
VAL_ 378 HVBSOCJumpError 1 "fault" 0 "No fault";
VAL_ 378 HVBHVILErr 1 "fault" 0 "No fault";
VAL_ 378 DCChrgSysShockErr 1 "fault" 0 "No fault";
VAL_ 378 BMS_READY 1 "Ready" 0 "Not ready";
VAL_ 378 HVBContactorSta 1 "Closed" 0 "Open";
VAL_ 378 HVBPrechrgSta 3 "precharge fail" 2 "precharge finished" 1 "precharge" 0 "not precharge";
VAL_ 378 HVBTempDiffErr 1 "fault" 0 "No fault";
VAL_ 378 HVILSta 1 "Opened" 0 "Closed";
VAL_ 378 HVBattReady4Pre 2 "Fault" 1 "Ready" 0 "Not Ready";
VAL_ 378 ChrgPlugSta 3 "Plug-in dectected" 2 "DC Plug in" 1 "AC Plug in" 0 "No plug";
VAL_ 378 ExtChrgSta 3 "Fault" 2 "Charging Completed" 1 "Charging" 0 "No action";
VAL_ 378 HVBPreheatPrecoolSta 2 "Precool" 1 "Preheat" 0 "Default";
VAL_ 378 IsoDetSta 1 "Fault detected" 0 "No fault detected";
VAL_ 378 SystemUncomErr 1 "fault" 0 "No fault";
VAL_ 378 CellUnconsistErr 1 "fault" 0 "No fault";
VAL_ 378 HVBCellOvrVoltWarn 2 "Warn2" 1 "Warn1" 0 "No fault";
VAL_ 378 HVBCellUdrVoltWarn 2 "Warn2" 1 "Warn1" 0 "No fault";
VAL_ 378 HVBCellOvrVoltErr 1 "fault" 0 "No fault";
VAL_ 378 HVBCellUndrVoltErr 1 "fault" 0 "No fault";
VAL_ 378 HVBCellUnbalanErr 1 "fault" 0 "No fault";
VAL_ 378 ChrgInLockReq 2 "Unlock" 1 "Lock" 0 "No action";
VAL_ 378 DisChrgPlugErr 2 "(un)lock request invalid" 1 "plug-in incomplete" 0 "Normal";
VAL_ 378 HVBChrgErr 4 "EVFault" 3 "EVStop" 2 "EvseFAULT" 1 "SocMeetTarget" 0 "OK";
VAL_ 378 V2LSta 3 "Invalid" 2 "SW on" 1 "V2L Adapter Plug-in" 0 "No plug";
VAL_ 380 ADAS_ForceIdle 1 "Force Idle" 0 "No Force Idle";
VAL_ 380 ADAS_ShftPosnReq 7 "Reverse" 4 "Ds" 3 "D" 2 "Neutral" 1 "Park" 0 "No Request";
VAL_ 380 ADAS_ShftPosnReq_A 1 "Applicable" 0 "Not Applicable";
VAL_ 383 CCMSA_SpdWar 1 "On" 0 "Off";
VAL_ 386 FD_AGS_Cmd 208 "78^Deg" 240 "90^Deg" 176 "66^Deg" 144 "54^Deg" 112 "42^Deg" 80 "30^Deg" 48 "18^Deg" 16 "6^Deg" 224 "84^Deg" 192 "72^Deg" 160 "60^Deg" 128 "48^Deg" 96 "36^Deg" 64 "24^Deg" 32 "12^Deg" 0 "0^Deg";
VAL_ 386 CabinMode 9 "Cabin Heating Mode 2" 8 "Cabin Heating Mode 1" 7 "Cabin Dehumidity Mode 4" 6 "Cabin Dehumidity Mode 3" 5 "Cabin Dehumidity Mode 2" 4 "Cabin Dehumidity Mode 1" 3 "Mode 1" 2 "Comp On" 1 "Comp Off" 0 "OFF";
VAL_ 386 BatteryMode 5 "Active Heating" 4 "Passive Heating" 3 "Isothermal Cycle" 2 "Passive Cooling" 1 "Active Cooling" 0 "OFF";
VAL_ 386 FD_RecyAuto_Cmd 6 "reserved" 5 "reserved" 4 "100% out recycle" 3 "70% out recycle" 2 "50% out recycle" 1 "30% out recycle" 0 "0% out recycle";
VAL_ 386 EDriveMode 2 "Waste Heat Recovery" 1 "Cooling" 0 "OFF";
VAL_ 386 HPThermalRecoveryReq 1 "Request" 0 "Not Request";
VAL_ 386 sigHvacSt 1 "ON" 0 "OFF";
VAL_ 386 sigRecircSt 1 "ON" 0 "OFF";
VAL_ 386 sigDfrstSt 1 "ON" 0 "OFF";
VAL_ 386 CCU_SyncLampSts 1 "Lamp ON" 0 "Lamp OFF";
VAL_ 386 sigAirIntenZon3St 15 "Invalid" 14 "Reserved" 11 "Reserved" 10 "NOT set" 9 "Level 8" 8 "Level 7" 7 "Level 6" 6 "Level 5" 5 "Level 4" 4 "Level 3" 3 "Level 2" 2 "Level 1" 1 "OFF" 0 "NO display / No request";
VAL_ 386 sigAirIntenZon1St 15 "Invalid" 14 "Reserved" 11 "Reserved" 10 "NOT set" 9 "Level 8" 8 "Level 7" 7 "Level 6" 6 "Level 5" 5 "Level 4" 4 "Level 3" 3 "Level 2" 2 "Level 1" 1 "OFF" 0 "NO display / No request";
VAL_ 386 sigWindDirZon3St 7 "NOT Set / Reserved" 6 "All open" 5 "Face + Screen" 4 "DEFOG" 3 "Foot + Screen" 2 "Foot" 1 "Bilevel" 0 "FACE";
VAL_ 386 CCU_FrtOnOffLampSts 1 "Lamp ON" 0 "Lamp OFF";
VAL_ 386 sigWindDirZon1St 7 "NOT Set / Reserved" 6 "All open" 5 "Face + Screen" 4 "DEFOG" 3 "Foot + Screen" 2 "Foot" 1 "Bilevel" 0 "FACE";
VAL_ 386 CCU_RrOnOffLampSts 1 "Lamp ON" 0 "Lamp OFF";
VAL_ 386 CCU_ACMaxLampSts 1 "Lamp ON" 0 "Lamp OFF";
VAL_ 386 CCU_AutoLampSts 1 "Lamp ON" 0 "Lamp OFF";
VAL_ 386 CCU_AutoMidLampSts 1 "Lamp ON" 0 "Lamp OFF";
VAL_ 386 CCU_EcoSts 1 "Lamp ON" 0 "Lamp OFF";
VAL_ 386 CCU_ACLampSts 1 "Lamp ON" 0 "Lamp OFF";
VAL_ 386 CCU_HEATMaxLampSts 1 "Lamp ON" 0 "Lamp OFF";
VAL_ 389 DCDCPreCompleted 2 "False" 1 "True" 0 "Default";
VAL_ 389 OBCPreCompleted 2 "Default" 1 "True" 0 "False";
VAL_ 389 OBCWakeup4Plugin 1 "True" 0 "False";
VAL_ 395 OBCV2LVinUVP 1 "Fault" 0 "Not Fault";
VAL_ 395 OBCV2LVinOVP 1 "Fault" 0 "Not Fault";
VAL_ 395 OBCV2LINVOTP 1 "Fault" 0 "Not Fault";
VAL_ 395 OBCV2LInsuFault 1 "Fault" 0 "Not Fault";
VAL_ 395 OBCV2LVoutOCP 1 "Fault" 0 "Not Fault";
VAL_ 395 OBCV2LVoutOVP 1 "Fault" 0 "Not Fault";
VAL_ 395 OBCV2LVoutUVP 1 "Fault" 0 "Not Fault";
VAL_ 402 Rr_MCUEnaSta 1 "Enable is ready" 0 "Disabled";
VAL_ 402 Rr_EDUOpratingSta 1 "Speed" 0 "Torque";
VAL_ 402 Rr_EDURotateDirction 2 "Backward" 1 "Forward" 0 "Stop";
VAL_ 402 Rr_MCUReady4Pre 1 "Ready for Precharge" 0 "Not Ready for Precharge";
VAL_ 402 Rr_ActvDmpDisabSta 1 "Disable" 0 "Enable";
VAL_ 402 Rr_EDUDrtSta 1 "Torque Derating" 0 "Normal operation";
VAL_ 402 Rr_MCUDischrgSta 1 "Discharge completed" 0 "Discharge not ready";
VAL_ 402 Rr_MCUReady 1 "Ready" 0 "Not Ready";
VAL_ 402 Rr_MCUErr 33 "Rolling counter_Err" 32 "Checksum_Err" 31 "BAT_High_Err" 30 "DrvrBrdOff" 29 "HWth3PHmax" 28 "AD2SInit_Err" 27 "B_OFFSET_Err" 26 "IGN_High_Err" 25 "IGBT_TEMP_sensing_Err" 24 "Motor_TEMP_sensing_Err" 23 "UVW_sensing_Err" 22 "UVW_unbalance" 21 "VPN_sensing_Err" 20 "IGN_Low_Err" 19 "BAT_Low_Err" 18 "Motor_TEMP_OVER" 17 "thRDX_ERROR" 16 "RDX_LOS" 15 "C_OFFSET_Err" 14 "A_OFFSET_Err" 13 "th3PHmax" 12 "H_sensor_Fault" 11 "VPN_250V" 10 "VPN_450V" 9 "HCU_miss" 8 "BMS_miss" 7 "UVW_open" 6 "IGBT_TEMP_OVER" 5 "P30BAT_ERR" 4 "DIR_ERR" 3 "Motor_speed_OVER" 2 "IGBT_FAULT" 1 "Motor_stuck" 0 "Nofault";
VAL_ 402 Rr_MCUIGN_sta 1 "MCU IGN On" 0 "MCU IGN Off";
VAL_ 402 Rr_MCUSysSta 15 "Not used" 14 "Not used" 13 "Not used" 12 "Not used" 11 "Not used" 10 "Not used" 9 "Resolver Adjust." 8 "Diag Service" 7 "Discharge" 6 "AfterRun" 5 "Failure" 4 "Speed Control" 3 "Torque Control" 2 "Ready" 1 "Stand by" 0 "Initial Diag";
VAL_ 402 MCUWarn_R 7 "MCU Normal(NO Error)" 3 "ERR LVL3" 2 "ERR LVL2" 1 "ERR LVL1" 0 "ERR LVL0";
VAL_ 406 Fr_MCUEnaSta 1 "Enable is ready" 0 "Disabled";
VAL_ 406 Fr_EDUOpratingSta 1 "Speed" 0 "Torque";
VAL_ 406 Fr_EDURotateDirction 2 "Backward" 1 "Forward" 0 "Stop";
VAL_ 406 Fr_MCUReady4Pre 1 "Ready for Precharge" 0 "Not Ready for Precharge";
VAL_ 406 Fr_ActvDmpDisabSta 1 "Disable" 0 "Enable";
VAL_ 406 Fr_EDUDrtSta 1 "Torque Derating" 0 "Normal operation";
VAL_ 406 Fr_MCUDischrgSta 1 "Discharge completed" 0 "Discharge not ready";
VAL_ 406 Fr_MCUErr 33 "Rolling counter_Err" 32 "Checksum_Err" 31 "BAT_High_Err" 30 "DrvrBrdOff" 29 "HWth3PHmax" 28 "AD2SInit_Err" 27 "B_OFFSET_Err" 26 "IGN_High_Err" 25 "IGBT_TEMP_sensing_Err" 24 "Motor_TEMP_sensing_Err" 23 "UVW_sensing_Err" 22 "UVW_unbalance" 21 "VPN_sensing_Err" 20 "IGN_Low_Err" 19 "BAT_Low_Err" 18 "Motor_TEMP_OVER" 17 "thRDX_ERROR" 16 "RDX_LOS" 15 "C_OFFSET_Err" 14 "A_OFFSET_Err" 13 "th3PHmax" 12 "H_sensor_Fault" 11 "VPN_250V" 10 "VPN_450V" 9 "HCU_miss" 8 "BMS_miss" 7 "UVW_open" 6 "IGBT_TEMP_OVER" 5 "P30BAT_ERR" 4 "DIR_ERR" 3 "Motor_speed_OVER" 2 "IGBT_FAULT" 1 "Motor_stuck" 0 "Nofault";
VAL_ 406 Fr_MCUIGN_sta 1 "MCU IGN On" 0 "MCU IGN Off";
VAL_ 406 Fr_MCUSysSta 15 "Not used" 14 "Not used" 13 "Not used" 12 "Not used" 11 "Not used" 10 "Not used" 9 "Resolver Adjust." 8 "Diag Service" 7 "Discharge" 6 "AfterRun" 5 "Failure" 4 "Speed Control" 3 "Torque Control" 2 "Ready" 1 "Stand by" 0 "Initial Diag";
VAL_ 406 MCUWarn_F 7 "MCU Normal(NO Error)" 3 "ERR LVL3" 2 "ERR LVL2" 1 "ERR LVL1" 0 "ERR LVL0";
VAL_ 406 Fr_MCUReady 1 "Ready" 0 "Not Ready";
VAL_ 408 Fr_Failcodehistory1 2 "Past failure" 1 "Latest failure" 0 "Nothing";
VAL_ 408 Fr_Failcodehistory2 2 "Past failure" 1 "Latest failure" 0 "Nothing";
VAL_ 408 Fr_TMTempWarn 2 "Reserve" 1 "Warning" 0 "Normal";
VAL_ 408 Fr_MCUTempWarn 2 "Reserve" 1 "Warning" 0 "Normal";
VAL_ 410 SAS_Speed_Valid 1 "Valid" 0 "Invalid";
VAL_ 410 SAS_CAL 1 "Calibrated" 0 "Non-calibrated";
VAL_ 410 SAS_V 1 "Valid" 0 "Invalid";
VAL_ 412 Rr_Failcodehistory1 2 "Past failure" 1 "Latest failure" 0 "Nothing";
VAL_ 412 Rr_Failcodehistory2 2 "Past failure" 1 "Latest failure" 0 "Nothing";
VAL_ 412 Rr_TMTempWarn 2 "Reserve" 1 "Warning" 0 "Normal";
VAL_ 412 Rr_MCUTempWarn 2 "Reserve" 1 "Warning" 0 "Normal";
VAL_ 419 Red_WnlmpSta 1 "Red Wnlmp constant" 0 "Red Wnlmp Off";
VAL_ 419 ABS_WnlmpSta 1 "ABS Wnlmp constant" 0 "ABS Wnlmp Off";
VAL_ 419 ESC_Off_lmpSta 1 "ESC OFF lmp permanent" 0 "ESC OFF lmp Off";
VAL_ 419 ESC_WnlmpSta 2 "ESC lmp flash" 1 "ESC lmp permanent" 0 "ESC lmp Off";
VAL_ 419 EBD_Active 1 "Active" 0 "Inactive";
VAL_ 419 ABS_Active 1 "Active" 0 "Inactive";
VAL_ 419 TCS_Active 1 "Active" 0 "Inactive";
VAL_ 419 ESC_Active 1 "Active" 0 "Inactive";
VAL_ 419 HBB_Active 1 "Active" 0 "Inactive";
VAL_ 419 PBA_Active 1 "Active" 0 "Inactive";
VAL_ 419 HSA_Active 1 "Active" 0 "Inactive";
VAL_ 419 AVH_Active 1 "Active" 0 "Inactive";
VAL_ 419 Amber_WnlmpSta 1 "Amber Wnlmp constant" 0 "Amber Wnlmp Off";
VAL_ 419 BTCS_Active 1 "Active" 0 "Inactive";
VAL_ 419 ESS_Active 1 "Active" 0 "Inactive";
VAL_ 419 HDD_Active 1 "Active" 0 "Inactive";
VAL_ 419 EBD_Failed 1 "Failed" 0 "Normal";
VAL_ 419 ABS_Failed 1 "Failed" 0 "Normal";
VAL_ 419 TCS_Failed 1 "Failed" 0 "Normal";
VAL_ 419 ESC_Failed 1 "Failed" 0 "Normal";
VAL_ 419 HBB_Failed 1 "Failed" 0 "Normal";
VAL_ 419 PBA_Failed 1 "Failed" 0 "Normal";
VAL_ 419 HSA_Failed 1 "Failed" 0 "Normal";
VAL_ 419 AVH_Failed 1 "Failed" 0 "Normal";
VAL_ 419 HDD_Failed 1 "Failed" 0 "Normal";
VAL_ 419 ESC_OFF_Status 2 "TCS and ESC OFF" 1 "TCS OFF" 0 "Normal";
VAL_ 419 ESC_BeepReq 1 "Request" 0 "No Request";
VAL_ 421 YawRate_V 1 "Invalid" 0 "Valid";
VAL_ 421 LatAccel_V 1 "Invalid" 0 "Valid";
VAL_ 421 LongAccel_V 1 "Invalid" 0 "Valid";
VAL_ 421 MCPressure_V 1 "Invalid" 0 "Valid";
VAL_ 421 BrkSw_Sta 1 "Active" 0 "Inactive";
VAL_ 421 BrkSw_V 1 "Invalid" 0 "Valid";
VAL_ 425 ACCAvail 1 "Available" 0 "Unavailable";
VAL_ 425 BrkDiscTempSta 1 "Over Temperature" 0 "Nomal";
VAL_ 425 ESC_Standstill 1 "Standstill" 0 "Not Standstill";
VAL_ 425 DecErrSta 1 "Error" 0 "Nomal";
VAL_ 425 ActBrkLamp_Sta 1 "On" 0 "Off";
VAL_ 425 AEBAvail 1 "Available" 0 "Unavailable";
VAL_ 425 ESC_ADAS_Sta 6 "Haptic Brake" 5 "Vehicle Standstill" 4 "Vehicle Holding" 3 "Deceleration Control" 2 "AEB Emergency Brake" 1 "Prefill" 0 "Internal";
VAL_ 425 ESC_APS_Sta 5 "APS Unavailable(ESC Failed)" 4 "Standstill with EPB" 3 "Standstill with Brake Hold" 2 "Decel Control" 1 "Standby(Ready)" 0 "Off";
VAL_ 427 EPBExtReleaseAvail 1 "Available" 0 "Unavailable";
VAL_ 427 EPBExtApplyAvail 1 "Available" 0 "Unavailable";
VAL_ 427 EPBCarWashMode 1 "Car Wash mode" 0 "Not Car wash mode";
VAL_ 427 DOA_Sta 1 "Enabled" 0 "Disabled";
VAL_ 427 EPBStaL 7 "Invalid" 6 "CompletelyReleased" 5 "Released" 4 "Releasing" 3 "Applying" 2 "HoldApplied" 1 "ParkApplied" 0 "Unknown";
VAL_ 427 TakeOverReq 1 "On (Controlled by Backup EPB)" 0 "Off (Controlled by ESC)";
VAL_ 427 EPBStaR 7 "Invalid" 6 "CompletelyReleased" 5 "Released" 4 "Releasing" 3 "Applying" 2 "HoldApplied" 1 "ParkApplied" 0 "Unknown";
VAL_ 427 EPBErrSta 2 "Diagnostic Mode" 1 "Failed" 0 "Normal";
VAL_ 427 EPBRLampSta 2 "Flash" 1 "Permanent" 0 "Off";
VAL_ 427 EPBSta 4 "Unknown" 3 "Releasing" 2 "Released" 1 "Applying" 0 "Applied";
VAL_ 427 EPBMsg 12 "Fasten driver seat belt" 11 "Press brake pedal to release Auto-Hold(Reserved)" 10 "Close driver side door(AVH)" 9 "EPB failed while AVH is activate" 8 "Please release park brake" 7 "Recalibration in progress" 6 "Depress Brake Pedal" 5 "Close driver-side door(DAR)" 4 "Rollerbench  Mode" 3 "Maintenance Mode" 2 "Slope Too Steep" 1 "Apply park brake" 0 "None";
VAL_ 470 OBCFaultSta 3 "Invalid" 2 "Any Fault" 1 "Working" 0 "Not Working";
VAL_ 470 DCDCFaultSta 3 "Any Fault LV2" 2 "Any Fault LV1" 1 "Working" 0 "Not Working";
VAL_ 470 OBCReady4Pre 1 "Ready" 0 "Not ready";
VAL_ 470 DCDCReady4Pre 1 "Ready" 0 "Not ready";
VAL_ 470 DCDCEnaSta 1 "DCDC enabled" 0 "DCDC disabled";
VAL_ 470 OBCPluginSta 1 "Plugin" 0 "Not Plugin";
VAL_ 470 OBCEnaSta 1 "Enabled" 0 "Disabled";
VAL_ 470 OBC_AC_Cur_Lim 3 "80A" 2 "45A" 1 "32A" 0 "16A";
VAL_ 470 OBCV2LSta 2 "Fault" 1 "Working" 0 "Not working";
VAL_ 470 ReqOBCV2LEna 2 "Internal V2L discharge" 1 "External V2L discharge" 0 "Not request for V2L discharge";
VAL_ 497 DrColumnSWFault 2 "Check fail" 1 "Check OK" 0 "No check";
VAL_ 497 DrTHCMFault 2 "Check fail" 1 "Check OK" 0 "No check";
VAL_ 497 DrPwrWindowECUFault 2 "Check fail" 1 "Check OK" 0 "No check";
VAL_ 497 DrInfoFault 2 "Check fail" 1 "Check OK" 0 "No check";
VAL_ 497 DrEOBDFault 2 "Check fail" 1 "Check OK" 0 "No check";
VAL_ 497 DrIVIFault 2 "Check fail" 1 "Check OK" 0 "No check";
VAL_ 497 DrPMMLimpHomeActReq 1 "Error" 0 "Normal";
VAL_ 497 DrPMMLVOutPErrLmp 1 "Error" 0 "Normal";
VAL_ 497 DrPMMSysErrLmp 1 "Error" 0 "Normal";
VAL_ 497 DrPwrSta 5 "READY" 4 "ON" 3 "STANDBY" 2 "OFF-After-Run" 1 "OFF-Charging" 0 "OFF";
VAL_ 497 DrPwrInformationSta 1 "ON" 0 "OFF";
VAL_ 497 ZDR_SYS_BSWSleepReq_Sta 1 "Request" 0 "No Request";
VAL_ 497 DrAPWLINErr 1 "Error" 0 "Normal";
VAL_ 497 DrAPWStaErr 1 "Error" 0 "Normal";
VAL_ 497 DrONA1ErrSta 1 "Error" 0 "Normal";
VAL_ 497 DrPwrWinErrSta 1 "Error" 0 "Normal";
VAL_ 497 DrStdAErrSta 1 "Error" 0 "Normal";
VAL_ 497 DrInfoErrSta 1 "Error" 0 "Normal";
VAL_ 497 ZoneDrMalfunLevel 5 "Invalid" 4 "4th grade malfunction" 3 "3rd grade malfunction" 2 "2nd grade malfunction" 1 "1st grade malfunction" 0 "Normal";
VAL_ 497 ZDR_VCU_HWReset_Sta 25 "EBM power off" 24 "ECompressor power off" 23 "WPTC power off" 22 "HMI power off" 21 "TBox power off" 20 "IVI power off" 19 "AirPTC power off" 18 "PSEAT power off" 17 "DSEAT power off" 16 "ABM power off" 15 "EPS power off" 14 "BMS power off" 13 "EOP_F power off" 12 "EOP_R power off" 11 "CCU power off" 10 "DKC power off" 9 "MRR power off" 8 "SRR_M power off" 7 "FCM power off" 6 "MCU_F power off" 5 "MCU_R power off" 4 "Shifter power off" 3 "Telltale power off" 2 "EBST power off" 1 "ESC power off" 0 "No request";
VAL_ 497 ZDR_VCU_PwrSupply_Sta 1 "Power supply off" 0 "No action";
VAL_ 498 FrPMMLimpHomeActReq 1 "Error" 0 "Normal";
VAL_ 498 FrPMMLVOutPErrLmp 1 "Error" 0 "Normal";
VAL_ 498 FrPMMSysErrLmp 1 "Error" 0 "Normal";
VAL_ 498 FrPwrStdbyA1Fault 2 "Check fail" 1 "Check OK" 0 "No check";
VAL_ 498 FrEDU_INVERTERFault 7 "Reserved" 6 "Reserved" 5 "Reserved" 4 "Reserved" 3 "Reserved" 2 "Reserved" 1 "Fault" 0 "Normal";
VAL_ 498 FrBMS_CCU_CIRFault 7 "Reserved" 6 "Reserved" 5 "Reserved" 4 "Reserved" 3 "Reserved" 2 "Reserved" 1 "Fault" 0 "Normal";
VAL_ 498 FrPwrONA1Fault 2 "Check fail" 1 "Check OK" 0 "No check";
VAL_ 498 FrPwrStdbyA2PlusFault 7 "Reserved" 6 "Reserved" 5 "Reserved" 4 "Reserved" 3 "Reserved" 2 "Reserved" 1 "Fault" 0 "Normal";
VAL_ 498 FrPwrStdbyA1PlusFault 7 "Reserved" 6 "Reserved" 5 "Reserved" 4 "Reserved" 3 "Reserved" 2 "Reserved" 1 "Fault" 0 "Normal";
VAL_ 498 ZoneFrMalfunLevel 5 "Invalid" 4 "4th grade malfunction" 3 "3rd grade malfunction" 2 "2nd grade malfunction" 1 "1st grade malfunction" 0 "Normal";
VAL_ 498 ZFR_SYS_BSWSleepReq_Sta 1 "Request" 0 "No Request";
VAL_ 498 FrBMSCCUCErr 1 "Error" 0 "Normal";
VAL_ 498 FrEDUErr 1 "Error" 0 "Normal";
VAL_ 498 FrStdA1PCErr 1 "Error" 0 "Normal";
VAL_ 498 FrStdA2PCErr 1 "Error" 0 "Normal";
VAL_ 498 FrStdA2PErr 1 "Error" 0 "Normal";
VAL_ 498 FrPwrSta 5 "READY" 4 "ON" 3 "STANDBY" 2 "OFF-After-Run" 1 "OFF-Charging" 0 "OFF";
VAL_ 498 ZFR_VCU_HWReset_Sta 25 "EBM power off" 24 "ECompressor power off" 23 "WPTC power off" 22 "HMI power off" 21 "TBox power off" 20 "IVI power off" 19 "AirPTC power off" 18 "PSEAT power off" 17 "DSEAT power off" 16 "ABM power off" 15 "EPS power off" 14 "BMS power off" 13 "EOP_F power off" 12 "EOP_R power off" 11 "CCU power off" 10 "DKC power off" 9 "MRR power off" 8 "SRR_M power off" 7 "FCM power off" 6 "MCU_F power off" 5 "MCU_R power off" 4 "Shifter power off" 3 "Telltale power off" 2 "EBST power off" 1 "ESC power off" 0 "No request";
VAL_ 498 ZFR_VCU_PwrSupply_Sta 1 "Power supply off" 0 "No action";
VAL_ 515 AirBagFailCmd 1 "Lamp ON" 0 "Lamp OFF";
VAL_ 515 DriverSeatBeltCmd 1 "Lamp ON" 0 "Lamp OFF";
VAL_ 515 PsngrSeatBeltCmd 1 "Lamp ON" 0 "Lamp OFF";
VAL_ 515 PABSwitchCmd 1 "Lamp ON" 0 "Lamp OFF";
VAL_ 515 RDriverSeatBeltCmd 1 "Lamp ON" 0 "Lamp OFF";
VAL_ 515 RPsngrSeatBeltCmd 1 "Lamp ON" 0 "Lamp OFF";
VAL_ 515 RCenterSeatBeltCmd 1 "Lamp ON" 0 "Lamp OFF";
VAL_ 515 TLHPsngrSeatBeltCmd 1 "Lamp ON" 0 "Lamp OFF";
VAL_ 515 TRHPsngrSeatBeltCmd 1 "Lamp ON" 0 "Lamp OFF";
VAL_ 515 CrashOutputSts 8 "Right hand side" 2 "Front First level" 16 "Left hand side" 0 "No crash";
VAL_ 517 SRR_RCTA_WarnR 1 "Warning" 0 "No Warning";
VAL_ 517 SRR_RCTA_WarnL 1 "Warning" 0 "No Warning";
VAL_ 517 SRR_BSD_WarnR 2 "Flash" 1 "Lit" 0 "No Warning";
VAL_ 517 SRR_BSD_WarnL 2 "Flash" 1 "Lit" 0 "No Warning";
VAL_ 517 SRR_BSD_SoundR 1 "On" 0 "Off";
VAL_ 517 SRR_BSD_SoundL 1 "On" 0 "Off";
VAL_ 517 SRR_BSD_Mute 1 "Mute" 0 "No Mute";
VAL_ 517 SRR_ODA_WarnR 2 "Flash" 1 "Lit" 0 "No Warning";
VAL_ 517 SRR_ODA_WarnL 2 "Flash" 1 "Lit" 0 "No Warning";
VAL_ 517 SRR_ODA_SoundR 1 "On" 0 "Off";
VAL_ 517 SRR_ODA_SoundL 1 "On" 0 "Off";
VAL_ 517 SRR_ODA_Mute 1 "Mute" 0 "No Mute";
VAL_ 517 SRR_ODA_Sta 5 "Disable" 4 "Blockage" 3 "Failure" 2 "Active" 1 "Standby" 0 "Off";
VAL_ 517 SRR_BSD_Sta 5 "Disable" 4 "Blockage" 3 "Failure" 2 "Active" 1 "Standby" 0 "Off";
VAL_ 517 SRR_RCTA_Sta 5 "Disable" 4 "Blockage" 3 "Failure" 2 "Active" 1 "Standby" 0 "Off";
VAL_ 517 SRR_FltWrnReq 1 "Warning" 0 "No Warning";
VAL_ 528 PAS_A_FCL 4 "level 4 (Far distance)" 3 "level 3" 2 "level 2" 1 "level 1 (Near distance)" 0 "No signal";
VAL_ 528 PAS_Chime 9 "APS change gear warning" 8 "R_USS Obstacle warning level 3" 7 "R_USS Obstacle warning level 2" 6 "R_USS Obstacle warning level 1" 5 "F_USS Obstacle warning level 3" 4 "F_USS Obstacle warning level 2" 3 "F_USS Obstacle warning level 1" 2 "PAS and APS check fault warning" 1 "PAS and APS check normal warning" 0 "No message";
VAL_ 528 APS_RQ_Display 44 "APS Cancelled because gear position is wrong" 43 "APS Cancelled because POWER is not ready" 42 "Please make sure the doors are closed and the seat belts are fastened." 41 "APS Cancelled because IVI or AVM is not ready" 40 "Driver seat belt is not fastened" 39 "Operation Timeout 2 min Please take over the vehicle" 38 "Operation Timeout 6 min Please take over the vehicle" 37 "Operation Timeout 1 min Please take over the vehicle" 36 "VCU failed Please take over steering" 35 "APS Cancelled because driver enable the EPB" 34 "APS Cancelled because driver intervenes the acceleration pedal" 33 "APS Cancelled because driver Intervention gear Please take over steering" 32 "APS Cancelled because driver Intervention brake Please take over steering" 31 "APS Cancelled because driver Intervention steering Please take over steering" 30 "APS Cancelled by driver" 29 "APS Cancelled because found the unknow object Please take over steering" 28 "APS Cancelled because the door is opened Please take over steering" 27 "The gear is changing to R-gear" 26 "The gear is changing to D-gear" 25 "Vehicle moving backward" 24 "Vehicle moving forward" 23 "APS System Error Please take over steering" 22 "Steering assistant failed Please take over steering" 21 "ESC failed Please take over steering" 20 "Auto parking assistant active Please check around" 19 "Shift to P gear now" 18 "Parking Slot Undersize Please take over steering" 17 "Operation Timeout Please take over the vehicle" 16 "APS Cancelled Please take over the vehicle" 15 "APS Cancelled because the speed is too fast" 14 "Stop and ready for auto parking" 13 "Please drive forward" 12 "Vehicle stop" 11 "Parking achieved" 10 "Parking out Cancelled because the slot is too small" 9 "Obstacles appear on the way of driving" 8 "The left side perpendicular parking slot be found" 7 "The left side parallel parking slot be found" 6 "The right side perpendicular parking slot be found" 5 "The right side  parallel parking slot be found" 4 "Searching for perpendicular parking slot on the left side" 3 "Searching for parallel parking slot on the left side" 2 "Searching for perpendicular parking slot on the right side" 1 "Searching for parallel parking slot on the right side" 0 "No message";
VAL_ 528 PAS_D_RMR 255 "FarDistance" 150 "Max" 0 "Min";
VAL_ 528 PAS_D_RML 255 "FarDistance" 150 "Max" 0 "Min";
VAL_ 528 PAS_D_RCR 255 "FarDistance" 150 "Max" 0 "Min";
VAL_ 528 PAS_D_RCL 255 "FarDistance" 150 "Max" 0 "Min";
VAL_ 528 APS_ExitCondition 51 "ENUM_EXC_OSPARK" 50 "ENUM_EXC_DCTOOFARSlOTFIND" 49 "ENUM_EXC_TO4OBSTFRONT" 48 "ENUM_EXC_TO4OBSTREAR" 46 "ENUM_EXC_OCDRIVERINTERF" 45 "ENUM_EXC_OCPPSTOOSMALL" 44 "ENUM_EXC_OCDOORSOPEN" 43 "ENUM_EXC_OCSWITCHOFFAPA" 42 "ENUM_EXC_OCSWITCHOFFPA" 41 "ENUM_EXC_OCWRONGDIR" 40 "ENUM_EXC_OTEPSERROR" 39 "ENUM_EXC_OTEVCUERROR" 38 "ENUM_EXC_OTBRAKEERROR" 37 "ENUM_EXC_OTGEARERROR" 36 "ENUM_EXC_OTEPBERROR" 35 "ENUM_EXC_OTCANERROR" 34 "ENUM_EXC_OTAPAERROR" 33 "ENUM_EXC_OTSENSORERROR" 32 "ENUM_EXC_OTOEMERROR" 81 "ENUM_EXC_OSSCA" 80 "ENUM_EXC_OSSCAWARNING" 79 "ENUM_EXC_DCTOOFARSCA" 77 "ENUM_EXC_OCSCADOORSOPEN" 76 "ENUM_EXC_OCSCASWITCHOFFAPA" 75 "ENUM_EXC_OCSCASWITCHOFFPA" 74 "ENUM_EXC_OCSCAWRONGDIR" 73 "ENUM_EXC_OTSCACAMERAERROR" 72 "ENUM_EXC_OTSCAEPSERROR" 71 "ENUM_EXC_OTSCAEVCUERROR" 70 "ENUM_EXC_OTSCABRAKEERROR" 69 "ENUM_EXC_OTSCAGEARERROR" 68 "ENUM_EXC_OTSCAEPBERROR" 131 "ENUM_EXC_TO4STANDING" 67 "ENUM_EXC_OTSCACANERROR" 130 "ENUM_EXC_TO4STANDSTILL" 66 "ENUM_EXC_OTSCAAPAERROR" 129 "ENUM_EXC_OCGEARCOUNT" 65 "ENUM_EXC_OTSCASENSORERROR" 64 "ENUM_EXC_OTSCAOEMERROR" 0 "ENUM_EXC_NOERROR";
VAL_ 528 PAS_D_FMR 255 "FarDistance" 150 "Max" 0 "Min";
VAL_ 528 PAS_D_FML 255 "FarDistance" 150 "Max" 0 "Min";
VAL_ 528 PAS_D_FCR 255 "FarDistance" 150 "Max" 0 "Min";
VAL_ 528 PAS_D_FCL 255 "FarDistance" 150 "Max" 0 "Min";
VAL_ 528 PAS_SNSR_Layout 7 "PAS_R2" 6 "PAS_R2F2" 5 "PAS_R4" 4 "PAS_F2R4" 3 "PAS_F4R4" 2 "APA" 1 "APS" 0 "Nomassage";
VAL_ 528 PAS_A_RMR 4 "level 4 (Far distance)" 3 "level 3" 2 "level 2" 1 "level 1 (Near distance)" 0 "No signal";
VAL_ 528 PAS_A_RML 4 "level 4 (Far distance)" 3 "level 3" 2 "level 2" 1 "level 1 (Near distance)" 0 "No signal";
VAL_ 528 PAS_A_RCR 4 "level 4 (Far distance)" 3 "level 3" 2 "level 2" 1 "level 1 (Near distance)" 0 "No signal";
VAL_ 528 PAS_A_RCL 4 "level 4 (Far distance)" 3 "level 3" 2 "level 2" 1 "level 1 (Near distance)" 0 "No signal";
VAL_ 528 PAS_A_FMR 4 "level 4 (Far distance)" 3 "level 3" 2 "level 2" 1 "level 1 (Near distance)" 0 "No signal";
VAL_ 528 PAS_A_FML 4 "level 4 (Far distance)" 3 "level 3" 2 "level 2" 1 "level 1 (Near distance)" 0 "No signal";
VAL_ 528 PAS_A_FCR 4 "level 4 (Far distance)" 3 "level 3" 2 "level 2" 1 "level 1 (Near distance)" 0 "No signal";
VAL_ 528 PAS_Sta_F_Sys 1 "Faliure" 0 "No Faliure";
VAL_ 528 PAS_Mod_Operation 3 "UDS" 2 "FUDS" 1 "RUDS" 0 "Function OFF";
VAL_ 528 USS_Sta_RMR 1 "Checked error" 0 "Checked OK";
VAL_ 528 USS_Sta_RML 1 "Checked error" 0 "Checked OK";
VAL_ 528 USS_Sta_RLR 1 "Checked error" 0 "Checked OK";
VAL_ 528 USS_Sta_RLL 1 "Checked error" 0 "Checked OK";
VAL_ 528 USS_Sta_RCR 1 "Checked error" 0 "Checked OK";
VAL_ 528 USS_Sta_RCL 1 "Checked error" 0 "Checked OK";
VAL_ 528 USS_Sta_FMR 1 "Checked error" 0 "Checked OK";
VAL_ 528 USS_Sta_FML 1 "Checked error" 0 "Checked OK";
VAL_ 528 USS_Sta_FLR 1 "Checked error" 0 "Checked OK";
VAL_ 528 USS_Sta_FLL 1 "Checked error" 0 "Checked OK";
VAL_ 528 USS_Sta_FCR 1 "Checked error" 0 "Checked OK";
VAL_ 528 USS_Sta_FCL 1 "Checked error" 0 "Checked OK";
VAL_ 528 FDC_VCU_RegenLimInd_Sta 1 "ON" 0 "OFF";
VAL_ 528 FDC_VCU_SmartEco_Sta 1 "ON" 0 "OFF";
VAL_ 528 FDC_VCU_SmartEcoSpdLim_Sta 1 "ON" 0 "OFF";
VAL_ 534 DrDoorSW 1 "Open" 0 "Close";
VAL_ 534 PsDoorSW 1 "Open" 0 "Close";
VAL_ 534 RLDoorSW 1 "Open" 0 "Close";
VAL_ 534 RRDoorSW 1 "Open" 0 "Close";
VAL_ 534 AllDoorSW 1 "Any Door Open" 0 "Close";
VAL_ 534 DoorLockIND 1 "On" 0 "Off";
VAL_ 534 HoodSW 1 "Open" 0 "Close";
VAL_ 534 Tailgate_SW 1 "Open" 0 "Close";
VAL_ 534 CTDCtrl 3 "Lock All Door" 2 "Unlock All Door" 1 "Unlock Driver Door" 0 "No Command";
VAL_ 534 Fr_ChargingDoorCtrl 3 "Undefined" 2 "Lock" 1 "Unlock" 0 "No Command";
VAL_ 534 Rr_ChargingDoorCtrl 3 "Undefined" 2 "Lock" 1 "Unlock" 0 "No Command";
VAL_ 534 CTDLockSW 1 "Press" 0 "Release";
VAL_ 534 CTDUnlockSW 1 "Press" 0 "Release";
VAL_ 534 MirrorDefog 1 "On" 0 "Off";
VAL_ 534 Rr_Defog 1 "On" 0 "Off";
VAL_ 534 TrunkRel 1 "Release" 0 "Off";
VAL_ 534 TailgateHDSW 1 "Press" 0 "Release";
VAL_ 534 MirrorCtrl 3 "Undefined" 2 "Unfold" 1 "Fold" 0 "No Command";
VAL_ 534 Fr_Wiper_H 1 "On" 0 "Off";
VAL_ 534 Fr_Wiper_L 1 "On" 0 "Off";
VAL_ 534 Rr_Wiper 1 "On" 0 "Off";
VAL_ 534 WiperFixMode 1 "On" 0 "Off";
VAL_ 534 WasherCtrl 3 "Undefined" 2 "Rear Washer" 1 "Front Washer" 0 "No Command";
VAL_ 534 L_Beam 1 "On" 0 "Off";
VAL_ 534 H_Beam 1 "On" 0 "Off";
VAL_ 534 PosLamp 1 "On" 0 "Off";
VAL_ 534 LDRL 1 "On" 0 "Off";
VAL_ 534 RDRL 1 "On" 0 "Off";
VAL_ 534 ReverseLamp 1 "On" 0 "Off";
VAL_ 534 BrakeLamp 1 "On" 0 "Off";
VAL_ 534 LBSD 1 "On" 0 "Off";
VAL_ 534 RBSD 1 "On" 0 "Off";
VAL_ 534 Fr_FogLamp 1 "On" 0 "Off";
VAL_ 534 Rr_FogLamp 1 "On" 0 "Off";
VAL_ 534 HazardSW 1 "On" 0 "Off";
VAL_ 534 LTurnLP 1 "On" 0 "Off";
VAL_ 534 RTurnLP 1 "On" 0 "Off";
VAL_ 534 AntitheftSta 3 "Alarm Status" 2 "Wait for Rearm Status" 1 "Arm Status" 0 "Disarm Status";
VAL_ 534 AntiTheftSeatFold 1 "Fold" 0 "No Request";
VAL_ 534 CrashDetd 1 "Crash detected" 0 "Crash not detected";
VAL_ 534 L_APM_WdwEnable 1 "Normal" 0 "Inhibit";
VAL_ 534 LockSetting 1 "Unlock Single Door" 0 "Unlock All Door";
VAL_ 534 BCM_Buzzer_Req 1 "Request" 0 "No Request";
VAL_ 534 TailgateRemote 3 "Invalid" 2 "Handle Request" 1 "Remote Request" 0 "No Request";
VAL_ 534 RoomLampL 1 "ON" 0 "OFF";
VAL_ 534 RoomLampH 1 "ON" 0 "OFF";
VAL_ 534 DimmerEN 1 "Enable" 0 "Disable";
VAL_ 534 BCM_DoorLock_Sta 1 "Lock" 0 "Unlock";
VAL_ 534 HornCtrl 1 "ON" 0 "OFF";
VAL_ 534 FollowMe 1 "On" 0 "Off";
VAL_ 534 APMDoorControlSta 1 "ON" 0 "OFF";
VAL_ 534 FDC_BCM_LockAlarm_Cmd 2 "Lock Fail" 1 "Lock" 0 "No Request";
VAL_ 534 FDC_THCM_APTCWarning_Sta 1 "Error" 0 "Normal";
